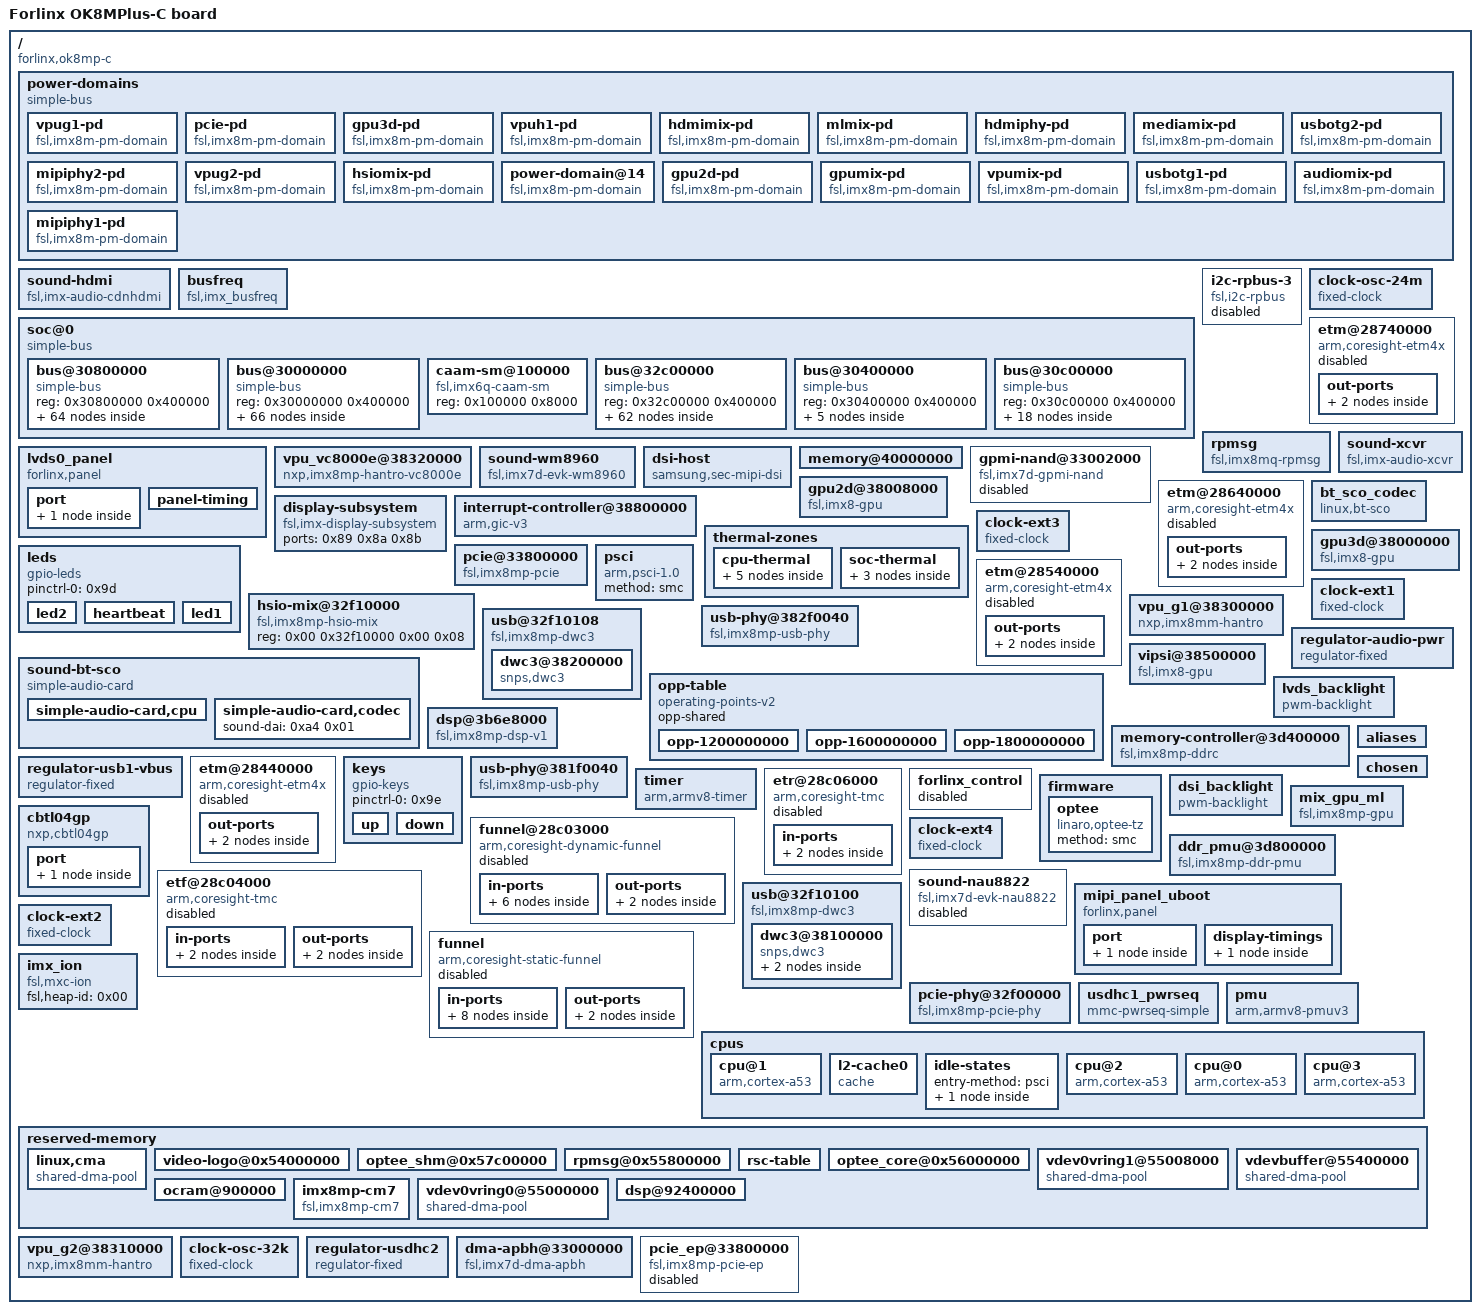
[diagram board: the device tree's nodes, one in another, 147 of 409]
/dts-v1/;

/ {
	#address-cells = <0x02>;
	model = "Forlinx OK8MPlus-C board";
	serial-number = "170e90004adaa6cb";
	#size-cells = <0x02>;
	interrupt-parent = <0x01>;
	compatible = "forlinx,ok8mp-c\0fsl,imx8mp-evk\0fsl,imx8mp";

	power-domains {
		compatible = "simple-bus";

		vpug1-pd {
			clocks = <0x03 0x106>;
			domain-name = "vpu_g1";
			#power-domain-cells = <0x00>;
			compatible = "fsl,imx8m-pm-domain";
			domain-index = <0x0a>;
			phandle = <0x83>;
			parent-domains = <0x0e>;
		};

		pcie-pd {
			domain-name = "pcie";
			#power-domain-cells = <0x00>;
			compatible = "fsl,imx8m-pm-domain";
			domain-index = <0x01>;
			phandle = <0x78>;
			parent-domains = <0x0c>;
		};

		gpu3d-pd {
			clocks = <0x03 0xf8 0x03 0x58>;
			domain-name = "gpu3d";
			#power-domain-cells = <0x00>;
			compatible = "fsl,imx8m-pm-domain";
			domain-index = <0x08>;
			phandle = <0x7d>;
			parent-domains = <0x0d>;
		};

		vpuh1-pd {
			clocks = <0x03 0x109>;
			domain-name = "vpu_h1";
			#power-domain-cells = <0x00>;
			compatible = "fsl,imx8m-pm-domain";
			domain-index = <0x0c>;
			phandle = <0x85>;
			parent-domains = <0x0e>;
		};

		hdmimix-pd {
			clocks = <0x03 0x116 0x03 0x63 0x03 0xa8>;
			domain-name = "hdmimix";
			#power-domain-cells = <0x00>;
			compatible = "fsl,imx8m-pm-domain";
			domain-index = <0x11>;
			phandle = <0x10>;
		};

		mlmix-pd {
			clocks = <0x03 0x69 0x03 0x6a 0x03 0x10b>;
			domain-name = "mlmix";
			#power-domain-cells = <0x00>;
			compatible = "fsl,imx8m-pm-domain";
			domain-index = <0x04>;
			phandle = <0x86>;
		};

		hdmiphy-pd {
			domain-name = "hdmi_phy";
			#power-domain-cells = <0x00>;
			compatible = "fsl,imx8m-pm-domain";
			domain-index = <0x12>;
			phandle = <0x6e>;
			parent-domains = <0x10>;
		};

		mediamix-pd {
			clocks = <0x03 0x10e 0x03 0x10d>;
			domain-name = "mediamix";
			#power-domain-cells = <0x00>;
			compatible = "fsl,imx8m-pm-domain";
			domain-index = <0x0d>;
			phandle = <0x0f>;
			rpm-always-on;
		};

		usbotg2-pd {
			domain-name = "usb_otg2";
			#power-domain-cells = <0x00>;
			compatible = "fsl,imx8m-pm-domain";
			domain-index = <0x03>;
			parent-domains = <0x0c>;
		};

		mipiphy2-pd {
			domain-name = "mipi_phy2";
			#power-domain-cells = <0x00>;
			compatible = "fsl,imx8m-pm-domain";
			domain-index = <0x10>;
			phandle = <0x75>;
			parent-domains = <0x0f>;
		};

		vpug2-pd {
			clocks = <0x03 0x10a>;
			domain-name = "vpu_g2";
			#power-domain-cells = <0x00>;
			compatible = "fsl,imx8m-pm-domain";
			domain-index = <0x0b>;
			phandle = <0x84>;
			parent-domains = <0x0e>;
		};

		hsiomix-pd {
			active-wakeup;
			domain-name = "hsiomix";
			#power-domain-cells = <0x00>;
			compatible = "fsl,imx8m-pm-domain";
			domain-index = <0x00>;
			phandle = <0x0c>;
			rpm-always-on;
		};

		power-domain@14 {
			clocks = <0x03 0x5c>;
			domain-name = "ispdwp";
			#power-domain-cells = <0x00>;
			compatible = "fsl,imx8m-pm-domain";
			domain-index = <0x0e>;
			phandle = <0x71>;
			parent-domains = <0x0f>;
		};

		gpu2d-pd {
			clocks = <0x03 0xf7>;
			domain-name = "gpu2d";
			#power-domain-cells = <0x00>;
			compatible = "fsl,imx8m-pm-domain";
			domain-index = <0x07>;
			phandle = <0x7e>;
			parent-domains = <0x0d>;
		};

		gpumix-pd {
			clocks = <0x03 0x107 0x03 0x66 0x03 0x65>;
			domain-name = "gpumix";
			#power-domain-cells = <0x00>;
			compatible = "fsl,imx8m-pm-domain";
			domain-index = <0x06>;
			phandle = <0x0d>;
		};

		vpumix-pd {
			clocks = <0x03 0x11a>;
			domain-name = "vpumix";
			#power-domain-cells = <0x00>;
			compatible = "fsl,imx8m-pm-domain";
			domain-index = <0x09>;
			phandle = <0x0e>;
		};

		usbotg1-pd {
			domain-name = "usb_otg1";
			#power-domain-cells = <0x00>;
			compatible = "fsl,imx8m-pm-domain";
			domain-index = <0x02>;
			parent-domains = <0x0c>;
		};

		audiomix-pd {
			clocks = <0x03 0x11c 0x03 0x5a>;
			domain-name = "audiomix";
			#power-domain-cells = <0x00>;
			compatible = "fsl,imx8m-pm-domain";
			domain-index = <0x05>;
			phandle = <0x56>;
		};

		mipiphy1-pd {
			domain-name = "mipi_phy1";
			#power-domain-cells = <0x00>;
			compatible = "fsl,imx8m-pm-domain";
			domain-index = <0x0f>;
			phandle = <0x5a>;
			parent-domains = <0x0f>;
			rpm-always-on;
		};
	};

	sound-hdmi {
		constraint-rate = <0xac44 0x15888 0x2b110 0x7d00 0xbb80 0x17700 0x2ee00>;
		model = "audio-hdmi";
		hdmi-out;
		compatible = "fsl,imx-audio-cdnhdmi";
		status = "okay";
		audio-cpu = <0xa5>;
	};

	busfreq {
		clock-names = "dram_pll\0dram_alt_src\0dram_apb_src\0dram_apb_pre_div\0dram_core\0dram_alt_root\0sys_pll1_40m\0sys_pll1_100m\0sys_pll2_333m\0noc_div\0ahb_div\0main_axi_src\0osc_24m\0sys_pll1_800m\0dram_pll_div";
		clocks = <0x03 0x29 0x03 0x70 0x03 0x71 0x03 0x71 0x03 0x11e 0x03 0x11d 0x03 0x30 0x03 0x32 0x03 0x3f 0x03 0x67 0x03 0x6b 0x03 0x5d 0x03 0x02 0x03 0x38 0x03 0x15>;
		compatible = "fsl,imx_busfreq";
	};

	soc@0 {
		#address-cells = <0x01>;
		#size-cells = <0x01>;
		compatible = "simple-bus";
		ranges = <0x00 0x00 0x00 0x3e000000>;

		bus@30800000 {
			#address-cells = <0x01>;
			#size-cells = <0x01>;
			compatible = "simple-bus";
			ranges;
			reg = <0x30800000 0x400000>;

			spi@30820000 {
				#address-cells = <0x01>;
				clock-names = "ipg\0per";
				assigned-clocks = <0x03 0x95>;
				assigned-clock-parents = <0x03 0x38>;
				assigned-clock-rates = <0x4c4b400>;
				interrupts = <0x00 0x1f 0x04>;
				clocks = <0x03 0xbd 0x03 0xbd>;
				#size-cells = <0x00>;
				dma-names = "rx\0tx";
				compatible = "fsl,imx8mp-ecspi\0fsl,imx6ul-ecspi";
				status = "disabled";
				reg = <0x30820000 0x10000>;
				dmas = <0x22 0x00 0x07 0x01 0x22 0x01 0x07 0x02>;
			};

			ethernet@30bf0000 {
				pinctrl-names = "default";
				phy-mode = "rgmii-id";
				intf_mode = <0x29 0x04>;
				nvmem-cells = <0x52>;
				pinctrl-0 = <0x53>;
				clock-names = "stmmaceth\0pclk\0ptp_ref\0tx";
				assigned-clocks = <0x03 0x5e 0x03 0x82 0x03 0x81>;
				assigned-clock-parents = <0x03 0x36 0x03 0x3a 0x03 0x3b>;
				local-mac-address = [26 6d dd 76 00 fb];
				assigned-clock-rates = <0x00 0x5f5e100 0x7735940>;
				interrupts = <0x00 0x86 0x04 0x00 0x87 0x04>;
				clocks = <0x03 0xed 0x03 0xe1 0x03 0x82 0x03 0x81>;
				nvmem_macaddr_swap;
				reset-gpio = <0x25 0x05 0x01>;
				compatible = "nxp,imx8mp-dwmac-eqos\0snps,dwmac-5.10a";
				status = "okay";
				interrupt-names = "eth_wake_irq\0macirq";
				nvmem-cell-names = "mac-address";
				reg = <0x30bf0000 0x10000>;
				phy-handle = <0x54>;

				mdio {
					#address-cells = <0x01>;
					#size-cells = <0x00>;
					compatible = "snps,dwmac-mdio";

					ethernet-phy@1 {
						at803x,vddio-1p8v;
						at803x,hibernate-disable;
						compatible = "ethernet-phy-ieee802.3-c22";
						eee-broken-1000t;
						reg = <0x01>;
						phandle = <0x54>;
					};
				};
			};

			i2c@30a50000 {
				pinctrl-names = "default";
				#address-cells = <0x01>;
				pinctrl-0 = <0x3e>;
				interrupts = <0x00 0x26 0x04>;
				clocks = <0x03 0xd0>;
				#size-cells = <0x00>;
				clock-frequency = <0x186a0>;
				compatible = "fsl,imx8mp-i2c\0fsl,imx21-i2c";
				status = "okay";
				reg = <0x30a50000 0x10000>;

				ft5316@38 {
					pinctrl-names = "default";
					pinctrl-0 = <0x3f>;
					interrupts = <0x0c 0x02>;
					interrupt-parent = <0x2e>;
					touchscreen-size-x = <0x400>;
					compatible = "edt,edt-ft5306";
					reg = <0x38>;
					touchscreen-size-y = <0x258>;
				};
			};

			serial@30a60000 {
				clock-names = "ipg\0per";
				interrupts = <0x00 0x1d 0x04>;
				clocks = <0x03 0xfe 0x03 0xfe>;
				dma-names = "rx\0tx";
				compatible = "fsl,imx8mp-uart\0fsl,imx6q-uart";
				status = "disabled";
				reg = <0x30a60000 0x10000>;
				dmas = <0x22 0x1c 0x04 0x00 0x22 0x1d 0x04 0x00>;
			};

			mmc@30b40000 {
				fsl,tuning-start-tap = <0x14>;
				pinctrl-names = "default\0state_100mhz\0state_200mhz";
				pinctrl-2 = <0x43 0x41>;
				pinctrl-0 = <0x40 0x41>;
				clock-names = "ipg\0ahb\0per";
				assigned-clocks = <0x03 0x88>;
				bus-width = <0x04>;
				non-removable;
				assigned-clock-rates = <0x17d78400>;
				interrupts = <0x00 0x16 0x04>;
				clocks = <0x03 0x00 0x03 0x5f 0x03 0x101>;
				keep-power-in-suspend;
				pm-ignore-notify;
				compatible = "fsl,imx8mm-usdhc\0fsl,imx7d-usdhc";
				pinctrl-1 = <0x42 0x41>;
				status = "okay";
				fsl,tuning-step = <0x02>;
				mmc-pwrseq = <0x44>;
				reg = <0x30b40000 0x10000>;
			};

			i2c@30ad0000 {
				#address-cells = <0x01>;
				interrupts = <0x00 0x4c 0x04>;
				clocks = <0x03 0xe7>;
				#size-cells = <0x00>;
				compatible = "fsl,imx8mp-i2c\0fsl,imx21-i2c";
				status = "disabled";
				reg = <0x30ad0000 0x10000>;
			};

			can@308d0000 {
				fsl,clk-source = <0x00>;
				pinctrl-names = "default";
				fsl,stop-mode = <0x29 0x10 0x05 0x10 0x15>;
				pinctrl-0 = <0x2b>;
				clock-names = "ipg\0per";
				assigned-clocks = <0x03 0x75>;
				assigned-clock-parents = <0x03 0x30>;
				assigned-clock-rates = <0x2625a00>;
				interrupts = <0x00 0x90 0x04>;
				clocks = <0x03 0x6e 0x03 0xea>;
				compatible = "fsl,imx8mp-flexcan\0fsl,imx6q-flexcan";
				status = "okay";
				reg = <0x308d0000 0x10000>;
			};

			spi@30830000 {
				pinctrl-names = "default";
				#address-cells = <0x01>;
				pinctrl-0 = <0x23 0x24>;
				clock-names = "ipg\0per";
				assigned-clocks = <0x03 0x96>;
				assigned-clock-parents = <0x03 0x38>;
				assigned-clock-rates = <0x4c4b400>;
				interrupts = <0x00 0x20 0x04>;
				clocks = <0x03 0xbe 0x03 0xbe>;
				#size-cells = <0x00>;
				dma-names = "rx\0tx";
				compatible = "fsl,imx8mp-ecspi\0fsl,imx6ul-ecspi";
				status = "okay";
				reg = <0x30830000 0x10000>;
				dmas = <0x22 0x02 0x07 0x01 0x22 0x03 0x07 0x02>;
				fsl,spi-num-chipselects = <0x01>;
				cs-gpios = <0x25 0x0d 0x01>;

				spi@0 {
					spi-max-frequency = <0x7a120>;
					compatible = "rohm,dh2228fv";
					reg = <0x00>;
				};
			};

			i2c@30a20000 {
				pinctrl-names = "default";
				#address-cells = <0x01>;
				pinctrl-0 = <0x2c>;
				interrupts = <0x00 0x23 0x04>;
				clocks = <0x03 0xcd>;
				#size-cells = <0x00>;
				clock-frequency = <0x186a0>;
				compatible = "fsl,imx8mp-i2c\0fsl,imx21-i2c";
				status = "okay";
				reg = <0x30a20000 0x10000>;

				pca9450@25 {
					gpio_intr = <0x2e 0x03 0x01>;
					pinctrl-0 = <0x2d>;
					compatible = "nxp,pca9450";
					reg = <0x25>;

					regulators {
						pca9450,pmic-buck2-dvs-voltage = <0xe7ef0 0xcf850>;
						#address-cells = <0x01>;
						pca9450,pmic-buck2-uses-i2c-dvs;
						#size-cells = <0x00>;

						regulator@1 {
							regulator-max-microvolt = <0x2160ec>;
							regulator-boot-on;
							regulator-always-on;
							regulator-min-microvolt = <0x927c0>;
							regulator-ramp-delay = <0xc35>;
							reg = <0x01>;
							phandle = <0x07>;
							regulator-compatible = "buck2";
						};

						regulator@8 {
							regulator-max-microvolt = <0x325aa0>;
							regulator-boot-on;
							regulator-always-on;
							regulator-min-microvolt = <0xc3500>;
							reg = <0x08>;
							regulator-compatible = "ldo3";
						};

						regulator@6 {
							regulator-max-microvolt = <0x325aa0>;
							regulator-boot-on;
							regulator-always-on;
							regulator-min-microvolt = <0x186a00>;
							reg = <0x06>;
							regulator-compatible = "ldo1";
						};

						regulator@4 {
							regulator-max-microvolt = <0x33e140>;
							regulator-boot-on;
							regulator-always-on;
							regulator-min-microvolt = <0x927c0>;
							reg = <0x04>;
							regulator-compatible = "buck5";
						};

						regulator@0 {
							regulator-max-microvolt = <0x2160ec>;
							regulator-boot-on;
							regulator-always-on;
							regulator-min-microvolt = <0x927c0>;
							regulator-ramp-delay = <0xc35>;
							reg = <0x00>;
							regulator-compatible = "buck1";
						};

						regulator@9 {
							regulator-max-microvolt = <0x325aa0>;
							regulator-boot-on;
							regulator-always-on;
							regulator-min-microvolt = <0xc3500>;
							reg = <0x09>;
							regulator-compatible = "ldo4";
						};

						regulator@7 {
							regulator-max-microvolt = <0x118c30>;
							regulator-boot-on;
							regulator-always-on;
							regulator-min-microvolt = <0xc3500>;
							reg = <0x07>;
							regulator-compatible = "ldo2";
						};

						regulator@5 {
							regulator-max-microvolt = <0x33e140>;
							regulator-boot-on;
							regulator-always-on;
							regulator-min-microvolt = <0x927c0>;
							reg = <0x05>;
							regulator-compatible = "buck6";
						};

						regulator@3 {
							regulator-max-microvolt = <0x33e140>;
							regulator-boot-on;
							regulator-always-on;
							regulator-min-microvolt = <0x927c0>;
							reg = <0x03>;
							regulator-compatible = "buck4";
						};

						regulator@10 {
							regulator-max-microvolt = <0x325aa0>;
							regulator-min-microvolt = <0x1b7740>;
							reg = <0x0a>;
							regulator-compatible = "ldo5";
						};
					};
				};
			};

			crypto@30900000 {
				#address-cells = <0x01>;
				clock-names = "aclk\0ipg";
				interrupts = <0x00 0x5b 0x04>;
				clocks = <0x03 0x6b 0x03 0x6e>;
				#size-cells = <0x01>;
				compatible = "fsl,sec-v4.0";
				ranges = <0x00 0x30900000 0x40000>;
				reg = <0x30900000 0x40000>;

				jr@2000 {
					interrupts = <0x00 0x6a 0x04>;
					compatible = "fsl,sec-v4.0-job-ring";
					reg = <0x2000 0x1000>;
				};

				jr@1000 {
					interrupts = <0x00 0x69 0x04>;
					compatible = "fsl,sec-v4.0-job-ring";
					reg = <0x1000 0x1000>;
				};

				jr@3000 {
					interrupts = <0x00 0x72 0x04>;
					compatible = "fsl,sec-v4.0-job-ring";
					status = "disabled";
					reg = <0x3000 0x1000>;
				};
			};

			mu@30aa0000 {
				clock-names = "mu";
				interrupts = <0x00 0x58 0x04>;
				clocks = <0x03 0xd5>;
				#mbox-cells = <0x02>;
				compatible = "fsl,imx8mp-mu\0fsl,imx6sx-mu";
				reg = <0x30aa0000 0x10000>;
				phandle = <0x08>;
			};

			spi@30bb0000 {
				pinctrl-names = "default";
				#address-cells = <0x01>;
				pinctrl-0 = <0x4e>;
				clock-names = "fspi\0fspi_en";
				reg-names = "fspi_base\0fspi_mmap";
				assigned-clocks = <0x03 0x87>;
				assigned-clock-rates = <0x4c4b400>;
				interrupts = <0x00 0x6b 0x04>;
				clocks = <0x03 0xe2 0x03 0xe2>;
				#size-cells = <0x00>;
				compatible = "nxp,imx8mm-fspi";
				status = "okay";
				reg = <0x30bb0000 0x10000 0x8000000 0x10000000>;

				mt25qu256aba@0 {
					#address-cells = <0x01>;
					spi-tx-bus-width = <0x04>;
					#size-cells = <0x01>;
					spi-max-frequency = <0x2faf080>;
					spi-rx-bus-width = <0x04>;
					compatible = "jedec,spi-nor";
					reg = <0x00>;
				};
			};

			serial@30880000 {
				pinctrl-names = "default";
				fsl,uart-has-rtscts;
				pinctrl-0 = <0x27>;
				clock-names = "ipg\0per";
				assigned-clocks = <0x03 0x90>;
				assigned-clock-parents = <0x03 0x31>;
				interrupts = <0x00 0x1c 0x04>;
				clocks = <0x03 0xfd 0x03 0xfd>;
				dma-names = "rx\0tx";
				compatible = "fsl,imx8mp-uart\0fsl,imx6q-uart";
				status = "okay";
				reg = <0x30880000 0x10000>;
				dmas = <0x22 0x1a 0x04 0x00 0x22 0x1b 0x04 0x00>;
			};

			dma-controller@30bd0000 {
				clock-names = "ipg\0ahb";
				interrupts = <0x00 0x02 0x04>;
				clocks = <0x03 0xec 0x03 0x6b>;
				fsl,sdma-ram-script-name = "imx/sdma/sdma-imx7d.bin";
				compatible = "fsl,imx8mq-sdma\0fsl,imx7d-sdma";
				reg = <0x30bd0000 0x10000>;
				phandle = <0x22>;
				#dma-cells = <0x03>;
			};

			mmc@30b50000 {
				fsl,tuning-start-tap = <0x14>;
				pinctrl-names = "default\0state_100mhz\0state_200mhz";
				pinctrl-2 = <0x48 0x46>;
				pinctrl-0 = <0x45 0x46>;
				clock-names = "ipg\0ahb\0per";
				assigned-clocks = <0x03 0x89>;
				bus-width = <0x04>;
				assigned-clock-rates = <0x17d78400>;
				interrupts = <0x00 0x17 0x04>;
				clocks = <0x03 0x00 0x03 0x5f 0x03 0x102>;
				vmmc-supply = <0x4a>;
				compatible = "fsl,imx8mm-usdhc\0fsl,imx7d-usdhc";
				pinctrl-1 = <0x47 0x46>;
				status = "okay";
				fsl,tuning-step = <0x02>;
				reg = <0x30b50000 0x10000>;
				cd-gpios = <0x49 0x0c 0x01>;
			};

			i2c@30ae0000 {
				#address-cells = <0x01>;
				interrupts = <0x00 0x4d 0x04>;
				clocks = <0x03 0xe8>;
				#size-cells = <0x00>;
				compatible = "fsl,imx8mp-i2c\0fsl,imx21-i2c";
				status = "disabled";
				reg = <0x30ae0000 0x10000>;
			};

			spi@30840000 {
				#address-cells = <0x01>;
				clock-names = "ipg\0per";
				assigned-clocks = <0x03 0xb3>;
				assigned-clock-parents = <0x03 0x38>;
				assigned-clock-rates = <0x4c4b400>;
				interrupts = <0x00 0x21 0x04>;
				clocks = <0x03 0xbf 0x03 0xbf>;
				#size-cells = <0x00>;
				dma-names = "rx\0tx";
				compatible = "fsl,imx8mp-ecspi\0fsl,imx6ul-ecspi";
				status = "disabled";
				reg = <0x30840000 0x10000>;
				dmas = <0x22 0x04 0x07 0x01 0x22 0x05 0x07 0x02>;
			};

			i2c@30a30000 {
				pinctrl-names = "default";
				#address-cells = <0x01>;
				pinctrl-0 = <0x2f>;
				interrupts = <0x00 0x24 0x04>;
				clocks = <0x03 0xce>;
				#size-cells = <0x00>;
				clock-frequency = <0x186a0>;
				compatible = "fsl,imx8mp-i2c\0fsl,imx21-i2c";
				status = "okay";
				reg = <0x30a30000 0x10000>;

				basler_camera_vvcam@36 {
					csi_id = <0x00>;
					compatible = "basler,basler-camera-vvcam\0basler-camera-vvcam";
					status = "okay";
					reg = <0x36>;

					port {

						endpoint {
							data-lanes = <0x01 0x02 0x03 0x04>;
							clock-lanes = <0x00>;
							remote-endpoint = <0x34>;
							phandle = <0x73>;
							link-frequencies = <0x00 0xec82e00>;
						};
					};
				};

				ov5645_mipi@3c {
					pinctrl-names = "default";
					pinctrl-0 = <0x30 0x31>;
					mipi_csi;
					clock-names = "xclk";
					assigned-clocks = <0x03 0xa5>;
					assigned-clock-parents = <0x03 0x02>;
					assigned-clock-rates = <0x16e3600>;
					clocks = <0x03 0xa5>;
					mclk_source = <0x00>;
					mclk = <0x16e3600>;
					clock-frequency = <0x16e3600>;
					csi_id = <0x01>;
					reset-gpios = <0x32 0x13 0x01>;
					compatible = "ovti,ov5645";
					status = "okay";
					enable-gpios = <0x32 0x14 0x00>;
					reg = <0x3c>;

					port {

						endpoint {
							data-lanes = <0x01 0x02>;
							clock-lanes = <0x00>;
							remote-endpoint = <0x33>;
							phandle = <0x76>;
							link-frequencies = <0x00 0x1406f400>;
						};
					};
				};
			};

			serial@30890000 {
				pinctrl-names = "default";
				pinctrl-0 = <0x28>;
				clock-names = "ipg\0per";
				interrupts = <0x00 0x1b 0x04>;
				clocks = <0x03 0xfc 0x03 0xfc>;
				compatible = "fsl,imx8mp-uart\0fsl,imx6q-uart";
				status = "okay";
				reg = <0x30890000 0x10000>;
			};

			mmc@30b60000 {
				fsl,tuning-start-tap = <0x14>;
				pinctrl-names = "default\0state_100mhz\0state_200mhz";
				pinctrl-2 = <0x4d>;
				pinctrl-0 = <0x4b>;
				clock-names = "ipg\0ahb\0per";
				assigned-clocks = <0x03 0xa9>;
				bus-width = <0x08>;
				non-removable;
				assigned-clock-rates = <0x17d78400>;
				interrupts = <0x00 0x18 0x04>;
				clocks = <0x03 0x00 0x03 0x5f 0x03 0x115>;
				compatible = "fsl,imx8mm-usdhc\0fsl,imx7d-usdhc";
				pinctrl-1 = <0x4c>;
				status = "okay";
				fsl,tuning-step = <0x02>;
				reg = <0x30b60000 0x10000>;
			};

			ethernet@30be0000 {
				pinctrl-names = "default";
				phy-mode = "rgmii-id";
				fsl,num-rx-queues = <0x03>;
				nvmem-cells = <0x4f>;
				pinctrl-0 = <0x50>;
				fsl,wakeup_irq = <0x02>;
				clock-names = "ipg\0ahb\0ptp\0enet_clk_ref\0enet_out";
				assigned-clocks = <0x03 0x5e 0x03 0x84 0x03 0x83 0x03 0x84>;
				assigned-clock-parents = <0x03 0x36 0x03 0x3a 0x03 0x3b>;
				fsl,num-tx-queues = <0x03>;
				local-mac-address = [26 6d dd 76 00 fa];
				assigned-clock-rates = <0x00 0x00 0x7735940 0x5f5e100>;
				interrupts = <0x00 0x76 0x04 0x00 0x77 0x04 0x00 0x78 0x04>;
				clocks = <0x03 0xc0 0x03 0xf2 0x03 0x84 0x03 0x83 0x03 0x85>;
				stop-mode = <0x29 0x10 0x03>;
				nvmem_macaddr_swap;
				reset-gpio = <0x25 0x04 0x01>;
				compatible = "fsl,imx8mm-fec\0fsl,imx8mq-fec\0fsl,imx6sx-fec";
				status = "okay";
				nvmem-cell-names = "mac-address";
				fsl,magic-packet;
				reg = <0x30be0000 0x10000>;
				phy-handle = <0x51>;

				mdio {
					#address-cells = <0x01>;
					#size-cells = <0x00>;

					ethernet-phy@1 {
						at803x,vddio-1p8v;
						compatible = "ethernet-phy-ieee802.3-c22";
						eee-broken-1000t;
						reg = <0x01>;
						phandle = <0x51>;
					};
				};
			};

			i2c@30a40000 {
				pinctrl-names = "default";
				#address-cells = <0x01>;
				pinctrl-0 = <0x35>;
				interrupts = <0x00 0x25 0x04>;
				clocks = <0x03 0xcf>;
				#size-cells = <0x00>;
				clock-frequency = <0x186a0>;
				compatible = "fsl,imx8mp-i2c\0fsl,imx21-i2c";
				status = "okay";
				reg = <0x30a40000 0x10000>;

				nau8822@1a {
					SPKVDD1-supply = <0x3c>;
					clock-names = "mclk";
					clocks = <0x3b 0x09>;
					compatible = "nuvoton,nau8822";
					wlf,shared-lrclk;
					status = "disabled";
					reg = <0x1a>;
					phandle = <0xa9>;
				};

				touchscreen@14 {
					pinctrl-names = "default";
					pinctrl-0 = <0x3d>;
					irq-gpios = <0x2e 0x00 0x00>;
					interrupts = <0x00 0x02>;
					interrupt-parent = <0x2e>;
					touchscreen-size-x = <0x500>;
					reset-gpios = <0x2e 0x0a 0x00>;
					compatible = "goodix,gt928";
					reg = <0x14>;
					touchscreen-swapped-x-y;
					edge-failling-trigger;
					touchscreen-size-y = <0x320>;
				};

				rx8010@32 {
					compatible = "epson,rx8010";
					status = "okay";
					reg = <0x32>;
				};

				wm8960@1a {
					SPKVDD1-supply = <0x3c>;
					clock-names = "mclk";
					clocks = <0x3b 0x09>;
					compatible = "wlf,wm8960";
					wlf,shared-lrclk;
					status = "okay";
					reg = <0x1a>;
					phandle = <0xa7>;
				};

				pcf8563@51 {
					clock-output-names = "pcf8563-clkout";
					#clock-cells = <0x00>;
					compatible = "nxp,pcf8563";
					reg = <0x51>;
				};

				typec-portc@22 {
					pinctrl-names = "default";
					pinctrl-0 = <0x36>;
					interrupts = <0x13 0x08>;
					vbus-supply = <0x37>;
					interrupt-parent = <0x38>;
					compatible = "fcs,fusb302";
					status = "okay";
					reg = <0x22>;
					phandle = <0x7f>;

					connector {
						sink-pdos = <0x4019096>;
						power-role = "dual";
						source-pdos = <0x4019096>;
						data-role = "dual";
						label = "USB-C";
						try-power-role = "sink";
						compatible = "usb-c-connector";
						op-sink-microwatt = <0x7270e0>;

						ports {
							#address-cells = <0x01>;
							#size-cells = <0x00>;

							port@1 {
								reg = <0x01>;

								endpoint {
									remote-endpoint = <0x3a>;
									phandle = <0xa1>;
								};
							};
						};
					};

					port {

						endpoint {
							remote-endpoint = <0x39>;
							phandle = <0x81>;
						};
					};
				};
			};

			serial@30860000 {
				pinctrl-names = "default";
				fsl,uart-has-rtscts;
				pinctrl-0 = <0x26>;
				clock-names = "ipg\0per";
				assigned-clocks = <0x03 0x8e>;
				assigned-clock-parents = <0x03 0x31>;
				interrupts = <0x00 0x1a 0x04>;
				clocks = <0x03 0xfb 0x03 0xfb>;
				dma-names = "rx\0tx";
				compatible = "fsl,imx8mp-uart\0fsl,imx6q-uart";
				status = "okay";
				reg = <0x30860000 0x10000>;
				dmas = <0x22 0x16 0x04 0x00 0x22 0x17 0x04 0x00>;
			};

			can@308c0000 {
				fsl,clk-source = <0x00>;
				pinctrl-names = "default";
				fsl,stop-mode = <0x29 0x10 0x04 0x10 0x14>;
				pinctrl-0 = <0x2a>;
				clock-names = "ipg\0per";
				assigned-clocks = <0x03 0x74>;
				assigned-clock-parents = <0x03 0x30>;
				assigned-clock-rates = <0x2625a00>;
				interrupts = <0x00 0x8e 0x04>;
				clocks = <0x03 0x6e 0x03 0xe9>;
				compatible = "fsl,imx8mp-flexcan\0fsl,imx6q-flexcan";
				status = "okay";
				reg = <0x308c0000 0x10000>;
			};
		};

		bus@30000000 {
			#address-cells = <0x01>;
			#size-cells = <0x01>;
			compatible = "simple-bus";
			ranges;
			reg = <0x30000000 0x400000>;

			snvs@30370000 {
				compatible = "fsl,sec-v4.0-mon\0syscon\0simple-mfd";
				reg = <0x30370000 0x10000>;
				phandle = <0x19>;

				snvs-powerkey {
					clock-names = "snvs";
					wakeup-source;
					interrupts = <0x00 0x04 0x04>;
					clocks = <0x03 0xf9>;
					compatible = "fsl,sec-v4.0-pwrkey";
					linux,keycode = <0x74>;
					regmap = <0x19>;
				};

				snvs-rtc-lp {
					clock-names = "snvs-rtc";
					interrupts = <0x00 0x13 0x04 0x00 0x14 0x04>;
					clocks = <0x03 0xf9>;
					offset = <0x34>;
					compatible = "fsl,sec-v4.0-mon-rtc-lp";
					regmap = <0x19>;
				};
			};

			ocotp-ctrl@30350000 {
				#address-cells = <0x01>;
				clocks = <0x03 0xd6>;
				#size-cells = <0x01>;
				compatible = "fsl,imx8mp-ocotp\0fsl,imx8mm-ocotp\0syscon";
				reg = <0x30350000 0x10000>;

				mac-address@650 {
					reg = <0x96 0x06>;
					phandle = <0x52>;
				};

				mac-address@640 {
					reg = <0x90 0x06>;
					phandle = <0x4f>;
				};

				speed-grade@10 {
					reg = <0x10 0x04>;
					phandle = <0x05>;
				};
			};

			clock-controller@30380000 {
				clock-names = "osc_32k\0osc_24m\0clk_ext1\0clk_ext2\0clk_ext3\0clk_ext4";
				assigned-clocks = <0x03 0x67 0x03 0x68 0x03 0x94 0x03 0x6c 0x03 0x48 0x03 0x6f 0x03 0x12 0x03 0x13 0x03 0x14>;
				assigned-clock-parents = <0x03 0x41 0x03 0x38 0x03 0x40 0x03 0x38 0x03 0x38>;
				init-on-array = <0x10c>;
				assigned-clock-rates = <0x3b9aca00 0x2faf0800 0x1dcd6500 0x17d78400 0x2faf0800 0x17d78400 0x17700000 0x15888000 0x3df582e0>;
				clocks = <0x1a 0x1b 0x1c 0x1d 0x1e 0x1f>;
				#clock-cells = <0x01>;
				compatible = "fsl,imx8mp-ccm";
				reg = <0x30380000 0x10000>;
				phandle = <0x03>;
			};

			src@30390000 {
				#reset-cells = <0x01>;
				interrupts = <0x00 0x59 0x04>;
				compatible = "fsl,imx8mp-src\0fsl,imx8mq-src\0syscon";
				reg = <0x30390000 0x10000>;
				phandle = <0x79>;
			};

			gpio@30230000 {
				gpio-controller;
				interrupts = <0x00 0x46 0x04 0x00 0x47 0x04>;
				clocks = <0x03 0xc4>;
				compatible = "fsl,imx8mp-gpio\0fsl,imx35-gpio";
				#interrupt-cells = <0x02>;
				reg = <0x30230000 0x10000>;
				phandle = <0x38>;
				#gpio-cells = <0x02>;
				interrupt-controller;
			};

			watchdog@30280000 {
				pinctrl-names = "default";
				pinctrl-0 = <0x17>;
				interrupts = <0x00 0x4e 0x04>;
				clocks = <0x03 0x103>;
				fsl,ext-reset-output;
				compatible = "fsl,imx8mp-wdt\0fsl,imx21-wdt";
				status = "okay";
				reg = <0x30280000 0x10000>;
			};

			gpio@30200000 {
				gpio-controller;
				interrupts = <0x00 0x40 0x04 0x00 0x41 0x04>;
				clocks = <0x03 0xc1>;
				compatible = "fsl,imx8mp-gpio\0fsl,imx35-gpio";
				#interrupt-cells = <0x02>;
				reg = <0x30200000 0x10000>;
				phandle = <0x2e>;
				#gpio-cells = <0x02>;
				interrupt-controller;
			};

			gpio@30240000 {
				gpio-controller;
				interrupts = <0x00 0x48 0x04 0x00 0x49 0x04>;
				clocks = <0x03 0xc5>;
				compatible = "fsl,imx8mp-gpio\0fsl,imx35-gpio";
				#interrupt-cells = <0x02>;
				reg = <0x30240000 0x10000>;
				phandle = <0x25>;
				#gpio-cells = <0x02>;
				interrupt-controller;
			};

			caam-snvs@30370000 {
				clock-names = "ipg";
				clocks = <0x03 0xf9>;
				compatible = "fsl,imx6q-caam-snvs";
				reg = <0x30370000 0x10000>;
			};

			gpio@30210000 {
				gpio-controller;
				interrupts = <0x00 0x42 0x04 0x00 0x43 0x04>;
				clocks = <0x03 0xc2>;
				compatible = "fsl,imx8mp-gpio\0fsl,imx35-gpio";
				#interrupt-cells = <0x02>;
				reg = <0x30210000 0x10000>;
				phandle = <0x49>;
				#gpio-cells = <0x02>;
				interrupt-controller;
			};

			anatop@30360000 {
				compatible = "fsl,imx8mp-anatop\0fsl,imx8mm-anatop\0syscon";
				reg = <0x30360000 0x10000>;
			};

			iomuxc-gpr@30340000 {
				compatible = "fsl,imx8mp-iomuxc-gpr\0fsl,imx7d-iomuxc-gpr\0fsl,imx6q-iomuxc-gpr\0syscon";
				reg = <0x30340000 0x10000>;
				phandle = <0x29>;
			};

			pinctrl@30330000 {
				pinctrl-names = "default";
				pinctrl-0 = <0x18>;
				compatible = "fsl,imx8mp-iomuxc";
				reg = <0x30330000 0x10000>;

				uart1grp {
					fsl,pins = <0x220 0x480 0x5e8 0x00 0x04 0x140 0x224 0x484 0x00 0x00 0x00 0x140 0x230 0x490 0x00 0x01 0x00 0x140 0x234 0x494 0x5e4 0x01 0x05 0x140>;
					phandle = <0x26>;
				};

				usdhc2grp-100mhz {
					fsl,pins = <0xc0 0x320 0x00 0x00 0x00 0x194 0xc4 0x324 0x00 0x00 0x00 0x1d4 0xc8 0x328 0x00 0x00 0x00 0x1d4 0xcc 0x32c 0x00 0x00 0x00 0x1d4 0xd0 0x330 0x00 0x00 0x00 0x1d4 0xd4 0x334 0x00 0x00 0x00 0x1d4 0x24 0x284 0x00 0x01 0x00 0xc1>;
					phandle = <0x47>;
				};

				flexcan2grp {
					fsl,pins = <0x1b4 0x414 0x550 0x03 0x01 0x154 0x1b0 0x410 0x00 0x03 0x00 0x154>;
					phandle = <0x2b>;
				};

				wdoggrp {
					fsl,pins = <0x1c 0x27c 0x00 0x01 0x00 0xc6>;
					phandle = <0x17>;
				};

				gpiokeygrp {
					fsl,pins = <0x1a8 0x408 0x00 0x05 0x00 0x159 0x190 0x3f0 0x00 0x05 0x00 0x159>;
					phandle = <0x9e>;
				};

				typec1grp {
					fsl,pins = <0x194 0x3f4 0x00 0x05 0x00 0x1c4>;
					phandle = <0x36>;
				};

				usb1grp {
					fsl,pins = <0x4c 0x2ac 0x00 0x00 0x00 0x19>;
					phandle = <0x9f>;
				};

				mipi_dsi_en {
					fsl,pins = <0x30 0x290 0x00 0x00 0x00 0x16>;
					phandle = <0x5d>;
				};

				csi0_rst_grp {
					fsl,pins = <0x12c 0x38c 0x00 0x05 0x00 0x19>;
					phandle = <0x31>;
				};

				ecspi2cs {
					fsl,pins = <0x1fc 0x45c 0x00 0x05 0x00 0x40000>;
					phandle = <0x24>;
				};

				i2c2grp {
					fsl,pins = <0x208 0x468 0x5ac 0x00 0x02 0x400001c3 0x20c 0x46c 0x5b0 0x00 0x02 0x400001c3>;
					phandle = <0x2f>;
				};

				usdhc3grp-200mhz {
					fsl,pins = <0x124 0x384 0x604 0x02 0x01 0x196 0x128 0x388 0x60c 0x02 0x01 0x1d6 0x108 0x368 0x610 0x02 0x01 0x1d6 0x10c 0x36c 0x614 0x02 0x01 0x1d6 0x110 0x370 0x618 0x02 0x01 0x1d6 0x114 0x374 0x61c 0x02 0x01 0x1d6 0x11c 0x37c 0x620 0x02 0x01 0x1d6 0xec 0x34c 0x624 0x02 0x01 0x1d6 0xf0 0x350 0x628 0x02 0x01 0x1d6 0xf4 0x354 0x62c 0x02 0x01 0x1d6 0xe8 0x348 0x630 0x02 0x01 0x196>;
					phandle = <0x4d>;
				};

				usdhc2grp {
					fsl,pins = <0xc0 0x320 0x00 0x00 0x00 0x190 0xc4 0x324 0x00 0x00 0x00 0x1d0 0xc8 0x328 0x00 0x00 0x00 0x1d0 0xcc 0x32c 0x00 0x00 0x00 0x1d0 0xd0 0x330 0x00 0x00 0x00 0x1d0 0xd4 0x334 0x00 0x00 0x00 0x1d0 0x24 0x284 0x00 0x01 0x00 0xc1>;
					phandle = <0x45>;
				};

				usdhc1grp-gpio {
					fsl,pins = <0xac 0x30c 0x00 0x05 0x00 0x41>;
					phandle = <0x41>;
				};

				gt928_int_iogrp {
					fsl,pins = <0x14 0x274 0x00 0x00 0x00 0x16 0x3c 0x29c 0x00 0x00 0x00 0x16>;
					phandle = <0x3d>;
				};

				uart3grp {
					fsl,pins = <0x1e0 0x440 0x5f8 0x01 0x04 0x140 0x1e4 0x444 0x00 0x01 0x00 0x140>;
					phandle = <0x27>;
				};

				gpioledgrp {
					fsl,pins = <0x1e8 0x448 0x00 0x05 0x00 0x19 0x1ec 0x44c 0x00 0x05 0x00 0x19>;
					phandle = <0x9d>;
				};

				pmicirq {
					fsl,pins = <0x20 0x280 0x00 0x00 0x00 0x41>;
					phandle = <0x2d>;
				};

				flexcan1grp {
					fsl,pins = <0x1ac 0x40c 0x54c 0x03 0x01 0x154 0x1a0 0x400 0x00 0x03 0x00 0x154>;
					phandle = <0x2a>;
				};

				sai3grp {
					fsl,pins = <0x1c4 0x424 0x4ec 0x00 0x01 0xd6 0x1c8 0x428 0x4e8 0x00 0x01 0xd6 0x1c0 0x420 0x4e4 0x00 0x01 0xd6 0x1cc 0x42c 0x00 0x00 0x00 0xd6 0x1d0 0x430 0x4e0 0x00 0x02 0xd6 0x1b8 0x418 0x00 0x05 0x00 0xd6 0x1bc 0x41c 0x00 0x05 0x00 0xd6>;
					phandle = <0x57>;
				};

				pciegrp {
					fsl,pins = <0x34 0x294 0x00 0x00 0x00 0x41>;
					phandle = <0x7c>;
				};

				usdhc3grp-100mhz {
					fsl,pins = <0x124 0x384 0x604 0x02 0x01 0x194 0x128 0x388 0x60c 0x02 0x01 0x1d4 0x108 0x368 0x610 0x02 0x01 0x1d4 0x10c 0x36c 0x614 0x02 0x01 0x1d4 0x110 0x370 0x618 0x02 0x01 0x1d4 0x114 0x374 0x61c 0x02 0x01 0x1d4 0x11c 0x37c 0x620 0x02 0x01 0x1d4 0xec 0x34c 0x624 0x02 0x01 0x1d4 0xf0 0x350 0x628 0x02 0x01 0x1d4 0xf4 0x354 0x62c 0x02 0x01 0x1d4 0xe8 0x348 0x630 0x02 0x01 0x194>;
					phandle = <0x4c>;
				};

				ft5x16_int_iogrp {
					fsl,pins = <0x44 0x2a4 0x00 0x00 0x00 0x16>;
					phandle = <0x3f>;
				};

				csi0_pwn_grp {
					fsl,pins = <0x130 0x390 0x00 0x05 0x00 0x19>;
					phandle = <0x30>;
				};

				usdhc1grp-200mhz {
					fsl,pins = <0x8c 0x2ec 0x00 0x00 0x00 0x196 0x90 0x2f0 0x00 0x00 0x00 0x1d6 0x94 0x2f4 0x00 0x00 0x00 0x1d6 0x98 0x2f8 0x00 0x00 0x00 0x1d6 0x9c 0x2fc 0x00 0x00 0x00 0x1d6 0xa0 0x300 0x00 0x00 0x00 0x1d6>;
					phandle = <0x43>;
				};

				csi_mclk_grp {
					fsl,pins = <0x50 0x2b0 0x00 0x06 0x00 0x59>;
				};

				i2c4grp {
					fsl,pins = <0x218 0x478 0x5bc 0x00 0x05 0x400001c3 0x21c 0x47c 0x5c0 0x00 0x05 0x400001c3>;
					phandle = <0x3e>;
				};

				i2c1grp {
					fsl,pins = <0x200 0x460 0x5a4 0x00 0x02 0x400001c3 0x204 0x464 0x5a8 0x00 0x02 0x400001c3>;
					phandle = <0x2c>;
				};

				usdhc1grp {
					fsl,pins = <0x8c 0x2ec 0x00 0x00 0x00 0x190 0x90 0x2f0 0x00 0x00 0x00 0x1d0 0x94 0x2f4 0x00 0x00 0x00 0x1d0 0x98 0x2f8 0x00 0x00 0x00 0x1d0 0x9c 0x2fc 0x00 0x00 0x00 0x1d0 0xa0 0x300 0x00 0x00 0x00 0x1d0>;
					phandle = <0x40>;
				};

				usdhc1grp-100mhz {
					fsl,pins = <0x8c 0x2ec 0x00 0x00 0x00 0x194 0x90 0x2f0 0x00 0x00 0x00 0x1d4 0x94 0x2f4 0x00 0x00 0x00 0x1d4 0x98 0x2f8 0x00 0x00 0x00 0x1d4 0x9c 0x2fc 0x00 0x00 0x00 0x1d4 0xa0 0x300 0x00 0x00 0x00 0x1d4>;
					phandle = <0x42>;
				};

				flexspi0grp {
					fsl,pins = <0xe0 0x340 0x00 0x01 0x00 0x1c2 0xe4 0x344 0x00 0x01 0x00 0x82 0xf8 0x358 0x00 0x01 0x00 0x82 0xfc 0x35c 0x00 0x01 0x00 0x82 0x100 0x360 0x00 0x01 0x00 0x82 0x104 0x364 0x00 0x01 0x00 0x82>;
					phandle = <0x4e>;
				};

				pwm2grp {
					fsl,pins = <0x40 0x2a0 0x00 0x02 0x00 0x116>;
					phandle = <0x21>;
				};

				uart2grp {
					fsl,pins = <0x228 0x488 0x5f0 0x00 0x06 0x49 0x22c 0x48c 0x00 0x00 0x00 0x49>;
					phandle = <0x28>;
				};

				sai5grp {
					fsl,pins = <0x138 0x398 0x510 0x03 0x00 0xd6 0x140 0x3a0 0x00 0x03 0x00 0xd6 0x144 0x3a4 0x4f0 0x00 0x00 0xd6 0x134 0x394 0x4f8 0x00 0x00 0xd6>;
					phandle = <0x58>;
				};

				lvds_panel_en {
					fsl,pins = <0x48 0x2a8 0x00 0x00 0x00 0x16>;
					phandle = <0xae>;
				};

				hoggrp {
					fsl,pins = <0x240 0x4a0 0x00 0x00 0x00 0x400001c3 0x244 0x4a4 0x00 0x00 0x00 0x400001c3 0x24c 0x4ac 0x00 0x00 0x00 0x40000019 0x248 0x4a8 0x00 0x00 0x00 0x40000019>;
					phandle = <0x18>;
				};

				fecgrp {
					fsl,pins = <0x158 0x3b8 0x00 0x04 0x00 0x03 0x15c 0x3bc 0x57c 0x04 0x01 0x03 0x160 0x3c0 0x580 0x04 0x01 0x91 0x164 0x3c4 0x584 0x04 0x01 0x91 0x168 0x3c8 0x00 0x04 0x00 0x91 0x16c 0x3cc 0x00 0x04 0x00 0x91 0x174 0x3d4 0x00 0x04 0x00 0x91 0x170 0x3d0 0x588 0x04 0x01 0x91 0x178 0x3d8 0x00 0x04 0x00 0x1f 0x17c 0x3dc 0x00 0x04 0x00 0x1f 0x180 0x3e0 0x00 0x04 0x00 0x1f 0x184 0x3e4 0x00 0x04 0x00 0x1f 0x188 0x3e8 0x00 0x04 0x00 0x1f 0x18c 0x3ec 0x00 0x04 0x00 0x1f 0x1d8 0x438 0x00 0x05 0x00 0x19>;
					phandle = <0x50>;
				};

				usdhc2grp-gpio {
					fsl,pins = <0xbc 0x31c 0x00 0x05 0x00 0x1c4 0xd8 0x338 0x00 0x05 0x00 0x41>;
					phandle = <0x46>;
				};

				usdhc2grp-200mhz {
					fsl,pins = <0xc0 0x320 0x00 0x00 0x00 0x196 0xc4 0x324 0x00 0x00 0x00 0x1d6 0xc8 0x328 0x00 0x00 0x00 0x1d6 0xcc 0x32c 0x00 0x00 0x00 0x1d6 0xd0 0x330 0x00 0x00 0x00 0x1d6 0xd4 0x334 0x00 0x00 0x00 0x1d6 0x24 0x284 0x00 0x01 0x00 0xc1>;
					phandle = <0x48>;
				};

				typec1muxgrp {
					fsl,pins = <0x198 0x3f8 0x00 0x05 0x00 0x16>;
					phandle = <0xa0>;
				};

				eqosgrp {
					fsl,pins = <0x54 0x2b4 0x00 0x00 0x00 0x03 0x58 0x2b8 0x590 0x00 0x01 0x03 0x7c 0x2dc 0x00 0x00 0x00 0x91 0x80 0x2e0 0x00 0x00 0x00 0x91 0x84 0x2e4 0x00 0x00 0x00 0x91 0x88 0x2e8 0x00 0x00 0x00 0x91 0x78 0x2d8 0x00 0x00 0x00 0x91 0x74 0x2d4 0x00 0x00 0x00 0x91 0x68 0x2c8 0x00 0x00 0x00 0x1f 0x64 0x2c4 0x00 0x00 0x00 0x1f 0x60 0x2c0 0x00 0x00 0x00 0x1f 0x5c 0x2bc 0x00 0x00 0x00 0x1f 0x6c 0x2cc 0x00 0x00 0x00 0x1f 0x70 0x2d0 0x00 0x00 0x00 0x1f 0x1dc 0x43c 0x00 0x05 0x00 0x19>;
					phandle = <0x53>;
				};

				i2c3grp {
					fsl,pins = <0x210 0x470 0x5b4 0x00 0x04 0x400001c3 0x214 0x474 0x5b8 0x00 0x04 0x400001c3>;
					phandle = <0x35>;
				};

				usdhc3grp {
					fsl,pins = <0x124 0x384 0x604 0x02 0x01 0x190 0x128 0x388 0x60c 0x02 0x01 0x1d0 0x108 0x368 0x610 0x02 0x01 0x1d0 0x10c 0x36c 0x614 0x02 0x01 0x1d0 0x110 0x370 0x618 0x02 0x01 0x1d0 0x114 0x374 0x61c 0x02 0x01 0x1d0 0x11c 0x37c 0x620 0x02 0x01 0x1d0 0xec 0x34c 0x624 0x02 0x01 0x1d0 0xf0 0x350 0x628 0x02 0x01 0x1d0 0xf4 0x354 0x62c 0x02 0x01 0x1d0 0xe8 0x348 0x630 0x02 0x01 0x190>;
					phandle = <0x4b>;
				};

				ecspi2grp {
					fsl,pins = <0x1f0 0x450 0x568 0x00 0x01 0x82 0x1f4 0x454 0x570 0x00 0x01 0x82 0x1f8 0x458 0x56c 0x00 0x01 0x82>;
					phandle = <0x23>;
				};

				pwm1grp {
					fsl,pins = <0x18 0x278 0x00 0x01 0x00 0x116>;
					phandle = <0x20>;
				};
			};

			caam_secvio {
				watchdog-tamper = "enabled";
				external-pin-tamper = "disabled";
				internal-boot-tamper = "enabled";
				interrupts = <0x00 0x14 0x04>;
				compatible = "fsl,imx6q-caam-secvio";
				jtag-tamper = "disabled";
			};

			gpio@30220000 {
				gpio-controller;
				interrupts = <0x00 0x44 0x04 0x00 0x45 0x04>;
				clocks = <0x03 0xc3>;
				compatible = "fsl,imx8mp-gpio\0fsl,imx35-gpio";
				#interrupt-cells = <0x02>;
				reg = <0x30220000 0x10000>;
				phandle = <0x32>;
				#gpio-cells = <0x02>;
				interrupt-controller;
			};

			tmu@30260000 {
				clocks = <0x03 0x119>;
				#thermal-sensor-cells = <0x01>;
				compatible = "fsl,imx8mp-tmu";
				reg = <0x30260000 0x10000>;
				phandle = <0x15>;
			};
		};

		caam-sm@100000 {
			compatible = "fsl,imx6q-caam-sm";
			reg = <0x100000 0x8000>;
		};

		bus@32c00000 {
			#address-cells = <0x01>;
			#size-cells = <0x01>;
			compatible = "simple-bus";
			ranges;
			reg = <0x32c00000 0x400000>;

			gasket@32ec0090 {
				compatible = "fsl,imx8mp-iomuxc-gpr\0syscon";
				reg = <0x32ec0090 0x28>;
				phandle = <0x74>;
			};

			gasket@32ec0060 {
				compatible = "fsl,imx8mp-iomuxc-gpr\0syscon";
				reg = <0x32ec0060 0x28>;
				phandle = <0x72>;
			};

			lcd-controller@32e90000 {
				power-domains = <0x0f>;
				#address-cells = <0x01>;
				clock-names = "pix\0disp-axi\0disp-apb";
				assigned-clocks = <0x03 0x121 0x03 0x61 0x03 0x62>;
				assigned-clock-parents = <0x03 0x28 0x03 0x41 0x03 0x38>;
				assigned-clock-rates = <0x00 0x1dcd6500 0xbebc200>;
				interrupts = <0x00 0x06 0x04>;
				clocks = <0x03 0x112 0x03 0x10e 0x03 0x10d>;
				#size-cells = <0x00>;
				compatible = "fsl,imx8mp-lcdif2";
				status = "okay";
				reg = <0x32e90000 0x10000>;

				port@0 {
					#address-cells = <0x01>;
					#size-cells = <0x00>;
					reg = <0x00>;
					phandle = <0x8a>;

					endpoint@1 {
						remote-endpoint = <0x62>;
						reg = <0x01>;
						phandle = <0x67>;
					};

					endpoint@0 {
						remote-endpoint = <0x61>;
						reg = <0x00>;
						phandle = <0x64>;
					};
				};
			};

			phy@32ec0128 {
				power-domains = <0x0f>;
				#address-cells = <0x01>;
				clock-names = "apb";
				clocks = <0x03 0x10d>;
				#size-cells = <0x00>;
				compatible = "fsl,imx8mp-lvds-phy";
				status = "okay";
				gpr = <0x5b>;

				port@0 {
					#phy-cells = <0x00>;
					reg = <0x00>;
					phandle = <0x63>;
				};

				port@1 {
					#phy-cells = <0x00>;
					reg = <0x01>;
					phandle = <0x66>;
				};
			};

			hdmiphy@32fdff00 {
				clock-output-names = "hdmi_phy";
				clock-names = "apb\0ref";
				resets = <0x69 0x01>;
				clocks = <0x68 0x1c 0x68 0x03>;
				#clock-cells = <0x01>;
				#phy-cells = <0x00>;
				compatible = "fsl,samsung-hdmi-phy";
				status = "disabled";
				reg = <0x32fdff00 0x100>;
				phandle = <0x6a>;
			};

			isi_chain@32e02000 {
				compatible = "fsl,imx8mp-iomuxc-gpr\0syscon";
				reg = <0x32e02000 0x04>;
				phandle = <0x70>;
			};

			camera {
				#address-cells = <0x01>;
				#size-cells = <0x01>;
				compatible = "fsl,mxc-md\0simple-bus";
				ranges;
				status = "okay";

				isp@32e20000 {
					power-domains = <0x71>;
					clock-names = "isp_root";
					assigned-clocks = <0x03 0x4a>;
					assigned-clock-parents = <0x03 0x40>;
					assigned-clock-rates = <0x1dcd6500>;
					id = <0x01>;
					interrupts = <0x00 0x4b 0x04>;
					clocks = <0x03 0x4a>;
					compatible = "fsl,imx8mp-isp";
					status = "disabled";
					reg = <0x32e20000 0x10000>;
				};

				isi@32e00000 {
					power-domains = <0x0f>;
					clock-names = "disp_axi\0disp_apb\0disp_axi_root\0disp_apb_root";
					assigned-clocks = <0x03 0x10e 0x03 0x10d>;
					assigned-clock-rates = <0x1dcd6500 0xbebc200>;
					interrupts = <0x00 0x10 0x04>;
					clocks = <0x03 0x61 0x03 0x62 0x03 0x10e 0x03 0x10d>;
					no-reset-control;
					compatible = "fsl,imx8mp-isi\0fsl,imx8mn-isi";
					status = "disabled";
					isi_chain = <0x70>;
					reg = <0x32e00000 0x2000>;
					interface = <0x02 0x00 0x02>;

					m2m_device {
						compatible = "imx-isi-m2m";
						status = "disabled";
					};

					cap_device {
						compatible = "imx-isi-capture";
						status = "disabled";
					};
				};

				isi@32e02000 {
					power-domains = <0x0f>;
					clock-names = "disp_axi\0disp_apb\0disp_axi_root\0disp_apb_root";
					assigned-clocks = <0x03 0x10e 0x03 0x10d>;
					assigned-clock-rates = <0x1dcd6500 0xbebc200>;
					interrupts = <0x00 0x2a 0x04>;
					clocks = <0x03 0x61 0x03 0x62 0x03 0x10e 0x03 0x10d>;
					no-reset-control;
					compatible = "fsl,imx8mp-isi\0fsl,imx8mn-isi";
					status = "okay";
					reg = <0x32e02000 0x2000>;
					interface = <0x03 0x00 0x02>;

					m2m_device {
						status = "okay";
					};

					cap_device {
						compatible = "imx-isi-capture";
						status = "okay";
					};
				};

				dwe@32e30000 {
					id = <0x00>;
					interrupts = <0x00 0x64 0x04>;
					compatible = "fsl,imx8mp-dwe";
					status = "okay";
					reg = <0x32e30000 0x10000>;
				};

				csi@32e40000 {
					power-domains = <0x5a>;
					#address-cells = <0x01>;
					clock-names = "mipi_clk\0disp_axi\0disp_apb";
					assigned-clocks = <0x03 0xaa>;
					assigned-clock-parents = <0x03 0x41>;
					bus-width = <0x04>;
					assigned-clock-rates = <0x1dcd6500>;
					interrupts = <0x00 0x11 0x04>;
					clocks = <0x03 0xaa 0x03 0x61 0x03 0x62>;
					#size-cells = <0x00>;
					no-reset-control;
					clock-frequency = <0x1dcd6500>;
					csi-gpr = <0x72>;
					compatible = "fsl,imx8mp-mipi-csi\0fsl,imx8mn-mipi-csi";
					status = "okay";
					reg = <0x32e40000 0x10000>;
					gpr = <0x5b>;

					port@0 {
						reg = <0x00>;

						endpoint {
							data-lanes = <0x04>;
							csis-hs-settle = <0x10>;
							remote-endpoint = <0x73>;
							phandle = <0x34>;
						};
					};
				};

				isp@32e10000 {
					power-domains = <0x71>;
					clock-names = "isp_root";
					assigned-clocks = <0x03 0x4a>;
					assigned-clock-parents = <0x03 0x40>;
					assigned-clock-rates = <0x1dcd6500>;
					id = <0x00>;
					interrupts = <0x00 0x4a 0x04>;
					clocks = <0x03 0x4a>;
					compatible = "fsl,imx8mp-isp";
					status = "okay";
					reg = <0x32e10000 0x10000>;
				};

				dwe_dup@32e30000 {
					id = <0x01>;
					interrupts = <0x00 0x64 0x04>;
					compatible = "fsl,imx8mp-dwe";
					status = "disabled";
					reg = <0x32e30000 0x10000>;
				};

				csi@32e50000 {
					power-domains = <0x75>;
					#address-cells = <0x01>;
					clock-names = "mipi_clk\0disp_axi\0disp_apb";
					assigned-clocks = <0x03 0xad>;
					assigned-clock-parents = <0x03 0x41>;
					bus-width = <0x04>;
					assigned-clock-rates = <0xfdad680>;
					interrupts = <0x00 0x50 0x04>;
					clocks = <0x03 0xad 0x03 0x61 0x03 0x62>;
					#size-cells = <0x00>;
					no-reset-control;
					clock-frequency = <0xfdad680>;
					csi-gpr = <0x74>;
					compatible = "fsl,imx8mp-mipi-csi\0fsl,imx8mn-mipi-csi";
					status = "okay";
					reg = <0x32e50000 0x10000>;
					gpr = <0x5b>;

					port@1 {
						reg = <0x01>;

						endpoint {
							data-lanes = <0x02>;
							csis-wclk;
							csis-hs-settle = <0x0d>;
							csis-clk-settle = <0x02>;
							remote-endpoint = <0x76>;
							phandle = <0x33>;
						};
					};
				};
			};

			blk-ctl@32ec0000 {
				clocks = <0x03 0x10d>;
				compatible = "fsl,imx8mp-mediamix-blk-ctl\0syscon";
				reg = <0x32ec0000 0x10000>;
				phandle = <0x5b>;
			};

			ldb@32ec005c {
				power-domains = <0x0f>;
				#address-cells = <0x01>;
				clock-names = "ldb";
				assigned-clocks = <0x03 0xae>;
				assigned-clock-parents = <0x03 0x28>;
				clocks = <0x03 0x122>;
				#size-cells = <0x00>;
				compatible = "fsl,imx8mp-ldb";
				status = "okay";
				gpr = <0x5b>;

				lvds-channel@0 {
					#address-cells = <0x01>;
					phy-names = "ldb_phy";
					#size-cells = <0x00>;
					fsl,data-mapping = "spwg";
					fsl,data-width = <0x18>;
					status = "okay";
					phys = <0x63>;
					reg = <0x00>;

					port@0 {
						reg = <0x00>;

						endpoint {
							remote-endpoint = <0x64>;
							phandle = <0x61>;
						};
					};

					port@1 {
						reg = <0x01>;

						endpoint {
							remote-endpoint = <0x65>;
							phandle = <0xaf>;
						};
					};
				};

				lvds-channel@1 {
					#address-cells = <0x01>;
					phy-names = "ldb_phy";
					#size-cells = <0x00>;
					status = "disabled";
					phys = <0x66>;
					reg = <0x01>;

					port@0 {
						reg = <0x00>;

						endpoint {
							remote-endpoint = <0x67>;
							phandle = <0x62>;
						};
					};
				};
			};

			hdmi@32fd8000 {
				power-domains = <0x6e>;
				phy-names = "hdmi";
				clock-names = "iahb\0isfr\0phy_int\0prep_clk\0skp_clk\0sfr_clk\0pix_clk\0cec_clk\0apb_clk\0hpi_clk\0fdcc_ref\0pipe_clk";
				assigned-clocks = <0x03 0x63 0x03 0x64 0x03 0xa7>;
				assigned-clock-parents = <0x03 0x38 0x03 0x40 0x03 0x02>;
				assigned-clock-rates = <0xbebc200 0x1dcd6500 0x16e3600>;
				resets = <0x69 0x00>;
				interrupts = <0x00 0x04>;
				clocks = <0x03 0x63 0x03 0xa7 0x68 0x1d 0x68 0x1b 0x68 0x1a 0x68 0x19 0x68 0x18 0x68 0x15 0x68 0x14 0x68 0x13 0x68 0x0e 0x68 0x24>;
				interrupt-parent = <0x6b>;
				compatible = "fsl,imx8mp-hdmi";
				status = "disabled";
				phys = <0x6a>;
				reg = <0x32fd8000 0x7eff>;
				gpr = <0x6d>;

				port@0 {

					endpoint {
						remote-endpoint = <0x6f>;
						phandle = <0x6c>;
					};
				};
			};

			irqsteer@32fc2000 {
				clock-names = "ipg";
				assigned-clocks = <0x03 0x63>;
				assigned-clock-parents = <0x03 0x38>;
				assigned-clock-rates = <0xbebc200>;
				resets = <0x69 0x05>;
				interrupts = <0x00 0x2b 0x04>;
				clocks = <0x68 0x06>;
				interrupt-parent = <0x01>;
				compatible = "fsl,imx-irqsteer";
				#interrupt-cells = <0x01>;
				status = "disabled";
				reg = <0x32fc2000 0x1000>;
				phandle = <0x6b>;
				fsl,num-irqs = <0x40>;
				fsl,channel = <0x01>;
				interrupt-controller;
			};

			hdmi-pai-pvi@32fc4000 {
				clock-names = "pvi_clk\0pai_clk";
				resets = <0x69 0x02 0x69 0x03>;
				clocks = <0x68 0x20 0x68 0x17>;
				compatible = "fsl,imx8mp-hdmi-pavi";
				status = "disabled";
				reg = <0x32fc4000 0x1000>;
				reset-names = "pai_rst\0pvi_rst";
			};

			hdmimix@32fc0000 {
				compatible = "fsl,imx8mp-audiomix\0fsl,imx8mp-hdmimix";
				reg = <0x32fc0000 0x1000>;

				clock-controller {
					clock-names = "dummy";
					clocks = <0x03 0x00>;
					#clock-cells = <0x01>;
					compatible = "fsl,imx8mp-hdmimix-clk";
					status = "disabled";
					phandle = <0x68>;
				};

				reset-controller {
					#reset-cells = <0x01>;
					compatible = "fsl,imx8mp-hdmimix-reset";
					status = "disabled";
					phandle = <0x69>;
				};
			};

			mipi_dsi@32e60000 {
				power-domains = <0x5a>;
				timing = <0x203>;
				#address-cells = <0x01>;
				clock-names = "cfg\0pll-ref";
				assigned-clocks = <0x03 0xab>;
				assigned-clock-parents = <0x03 0x02>;
				assigned-clock-rates = <0x16e3600>;
				interrupts = <0x00 0x12 0x04>;
				timing2 = <0x30305>;
				clocks = <0x03 0x10d 0x03 0xab>;
				#size-cells = <0x00>;
				compatible = "fsl,imx8mp-mipi-dsim";
				status = "okay";
				pmsreg = <0x8644>;
				reg = <0x32e60000 0x10000>;
				blk-ctl = <0x5b>;
				timing1 = <0x20d0803>;

				port@0 {

					endpoint {
						remote-endpoint = <0x5c>;
						phandle = <0x60>;
					};
				};

				port@1 {

					endpoint {
						remote-endpoint = <0x5f>;
						phandle = <0xb0>;
					};
				};

				mipi_panel {
					panel-height-mm = <0x79>;
					pinctrl-names = "default";
					video-mode = <0x02>;
					pinctrl-0 = <0x5d>;
					backlight = <0x5e>;
					panel-width-mm = <0x44>;
					enable-gpio = <0x2e 0x07 0x00>;
					compatible = "forlinx,mipi-dsi";
					status = "okay";
					dsi-lanes = <0x04>;
					reg = <0x00>;

					display-timings {

						timings {
							vfront-porch = <0x0c>;
							vback-porch = <0x17>;
							de-active = <0x00>;
							hsync-len = <0x46>;
							vactive = <0x258>;
							clock-frequency = <0x2aea540>;
							hsync-active = <0x00>;
							hactive = <0x400>;
							vsync-active = <0x00>;
							vsync-len = <0x0a>;
							pixelclk-active = <0x00>;
							hback-porch = <0xa0>;
							hfront-porch = <0xa0>;
						};
					};
				};
			};

			hdmi-blk@32fc0000 {
				compatible = "syscon";
				reg = <0x32fc0000 0x1000>;
				phandle = <0x6d>;
			};

			media_gpr@32ec0008 {
				compatible = "fsl,imx8mp-iomuxc-gpr\0syscon";
				reg = <0x32ec0008 0x04>;
			};

			lcd-controller@32fc6000 {
				power-domains = <0x10>;
				#address-cells = <0x01>;
				clock-names = "pix\0disp-axi\0disp-apb\0mix_apb\0mix_axi\0xtl_24m\0mix_pix\0lcdif_apb\0lcdif_axi\0lcdif_pdi\0lcdif_pix\0lcdif_spu\0noc_hdmi";
				assigned-clocks = <0x03 0x64 0x03 0x63>;
				assigned-clock-parents = <0x03 0x40 0x03 0x38>;
				assigned-clock-rates = <0x1dcd6500 0xbebc200>;
				resets = <0x69 0x07>;
				interrupts = <0x08 0x04>;
				clocks = <0x6a 0x00 0x03 0x64 0x03 0x63 0x68 0x00 0x68 0x01 0x68 0x03 0x68 0x05 0x68 0x09 0x68 0x0a 0x68 0x0b 0x68 0x0c 0x68 0x0d 0x68 0x07>;
				thres-low = <0x01 0x02>;
				#size-cells = <0x00>;
				interrupt-parent = <0x6b>;
				compatible = "fsl,imx8mp-lcdif3";
				thres-high = <0x03 0x04>;
				status = "disabled";
				reg = <0x32fc6000 0x10000>;

				port@0 {
					reg = <0x00>;
					phandle = <0x8b>;

					endpoint {
						remote-endpoint = <0x6c>;
						phandle = <0x6f>;
					};
				};
			};

			lcd-controller@32e80000 {
				power-domains = <0x0f>;
				#address-cells = <0x01>;
				clock-names = "pix\0disp-axi\0disp-apb";
				assigned-clocks = <0x03 0xac 0x03 0x61 0x03 0x62>;
				assigned-clock-parents = <0x03 0x28 0x03 0x41 0x03 0x38>;
				assigned-clock-rates = <0x00 0x1dcd6500 0xbebc200>;
				interrupts = <0x00 0x05 0x04>;
				clocks = <0x03 0x111 0x03 0x10e 0x03 0x10d>;
				#size-cells = <0x00>;
				compatible = "fsl,imx8mp-lcdif1";
				status = "disabled";
				reg = <0x32e80000 0x10000>;
				blk-ctl = <0x5b>;

				port@0 {
					reg = <0x00>;
					phandle = <0x89>;

					endpoint {
						remote-endpoint = <0x60>;
						phandle = <0x5c>;
					};
				};
			};
		};

		bus@30400000 {
			#address-cells = <0x01>;
			#size-cells = <0x01>;
			compatible = "simple-bus";
			ranges;
			reg = <0x30400000 0x400000>;

			pwm@30670000 {
				pinctrl-names = "default";
				pinctrl-0 = <0x21>;
				clock-names = "ipg\0per";
				interrupts = <0x00 0x52 0x04>;
				clocks = <0x03 0xdd 0x03 0xdd>;
				#pwm-cells = <0x02>;
				compatible = "fsl,imx8mp-pwm\0fsl,imx27-pwm";
				status = "okay";
				reg = <0x30670000 0x10000>;
				phandle = <0xab>;
			};

			pwm@30680000 {
				clock-names = "ipg\0per";
				interrupts = <0x00 0x53 0x04>;
				clocks = <0x03 0xde 0x03 0xde>;
				#pwm-cells = <0x02>;
				compatible = "fsl,imx8mp-pwm\0fsl,imx27-pwm";
				status = "disabled";
				reg = <0x30680000 0x10000>;
			};

			pwm@30690000 {
				clock-names = "ipg\0per";
				interrupts = <0x00 0x54 0x04>;
				clocks = <0x03 0xdf 0x03 0xdf>;
				#pwm-cells = <0x02>;
				compatible = "fsl,imx8mp-pwm\0fsl,imx27-pwm";
				status = "disabled";
				reg = <0x30690000 0x10000>;
			};

			pwm@30660000 {
				pinctrl-names = "default";
				pinctrl-0 = <0x20>;
				clock-names = "ipg\0per";
				assigned-clocks = <0x03 0x97>;
				assigned-clock-parents = <0x03 0x02>;
				assigned-clock-rates = <0x16e3600>;
				interrupts = <0x00 0x51 0x04>;
				clocks = <0x03 0xdc 0x03 0xdc>;
				#pwm-cells = <0x02>;
				compatible = "fsl,imx8mp-pwm\0fsl,imx27-pwm";
				status = "okay";
				reg = <0x30660000 0x10000>;
				phandle = <0xac>;
			};

			timer@306a0000 {
				clock-names = "per";
				interrupts = <0x00 0x2f 0x04>;
				clocks = <0x1b>;
				compatible = "nxp,sysctr-timer";
				reg = <0x306a0000 0x20000>;
			};
		};

		bus@30c00000 {
			#address-cells = <0x01>;
			#size-cells = <0x01>;
			compatible = "simple-bus";
			ranges;
			reg = <0x30c00000 0x400000>;

			spba-bus@30c00000 {
				#address-cells = <0x01>;
				#size-cells = <0x01>;
				compatible = "fsl,spba-bus\0simple-bus";
				ranges;
				reg = <0x30c00000 0x100000>;

				sai@30c20000 {
					power-domains = <0x56>;
					clock-names = "bus\0mclk0\0mclk1\0mclk2\0mclk3";
					fsl,dataline = <0x00 0x0f 0x0f>;
					interrupts = <0x00 0x60 0x04>;
					clocks = <0x3b 0x04 0x03 0x00 0x3b 0x05 0x03 0x00 0x03 0x00>;
					dma-names = "rx\0tx";
					compatible = "fsl,imx8mq-sai\0fsl,imx6sx-sai";
					fsl,shared-interrupt;
					status = "disabled";
					reg = <0x30c20000 0x10000>;
					dmas = <0x55 0x02 0x02 0x00 0x55 0x03 0x02 0x00>;
				};

				sai@30c60000 {
					power-domains = <0x56>;
					clock-names = "bus\0mclk0\0mclk1\0mclk2\0mclk3";
					interrupts = <0x00 0x5a 0x04>;
					clocks = <0x3b 0x10 0x03 0x00 0x3b 0x11 0x03 0x00 0x03 0x00>;
					dma-names = "rx\0tx";
					compatible = "fsl,imx8mq-sai\0fsl,imx6sx-sai";
					fsl,shared-interrupt;
					status = "disabled";
					reg = <0x30c60000 0x10000>;
					dmas = <0x55 0x0a 0x02 0x00 0x55 0x0b 0x02 0x00>;
				};

				micfil@30ca0000 {
					power-domains = <0x56>;
					clock-names = "ipg_clk\0ipg_clk_app\0pll8k\0pll11k\0clkext3";
					interrupts = <0x00 0x6d 0x04 0x00 0x6e 0x04 0x00 0x2c 0x04 0x00 0x2d 0x04>;
					clocks = <0x3b 0x19 0x3b 0x27 0x03 0x26 0x03 0x27 0x03 0x06>;
					dma-names = "rx";
					compatible = "fsl,imx8mp-micfil";
					status = "disabled";
					reg = <0x30ca0000 0x10000>;
					dmas = <0x55 0x18 0x19 0x80000000>;
				};

				xcvr@30cc0000 {
					power-domains = <0x56>;
					clock-names = "ipg\0phy\0spba\0pll_ipg";
					reg-names = "ram\0regs\0rxfifo\0txfifo";
					resets = <0x59 0x00>;
					interrupts = <0x00 0x80 0x04 0x00 0x81 0x04 0x00 0x92 0x04>;
					clocks = <0x3b 0x1f 0x3b 0x26 0x3b 0x1c 0x3b 0x23>;
					dma-names = "rx\0tx";
					#sound-dai-cells = <0x00>;
					compatible = "fsl,imx8mp-xcvr";
					status = "okay";
					reg = <0x30cc0000 0x800 0x30cc0800 0x400 0x30cc0c00 0x80 0x30cc0e00 0x80>;
					phandle = <0xaa>;
					dmas = <0x55 0x1e 0x02 0x00 0x55 0x1f 0x02 0x00>;
				};

				sai@30c30000 {
					power-domains = <0x56>;
					pinctrl-names = "default";
					pinctrl-0 = <0x57>;
					clock-names = "bus\0mclk0\0mclk1\0mclk2\0mclk3";
					assigned-clocks = <0x03 0x7d>;
					assigned-clock-parents = <0x03 0x26>;
					fsl,dataline = <0x00 0x03 0x03>;
					assigned-clock-rates = <0xbb8000>;
					interrupts = <0x00 0x32 0x04>;
					clocks = <0x3b 0x08 0x03 0x00 0x3b 0x09 0x03 0x00 0x03 0x00>;
					dma-names = "rx\0tx";
					compatible = "fsl,imx8mq-sai\0fsl,imx6sx-sai";
					fsl,shared-interrupt;
					status = "okay";
					fsl,sai-mclk-direction-output;
					reg = <0x30c30000 0x10000>;
					phandle = <0xa6>;
					dmas = <0x55 0x04 0x02 0x00 0x55 0x05 0x02 0x00>;
				};

				sai@30c80000 {
					power-domains = <0x56>;
					clock-names = "bus\0mclk0\0mclk1\0mclk2\0mclk3";
					interrupts = <0x00 0x6f 0x04>;
					clocks = <0x3b 0x14 0x03 0x00 0x3b 0x15 0x03 0x00 0x03 0x00>;
					dma-names = "rx\0tx";
					compatible = "fsl,imx8mq-sai\0fsl,imx6sx-sai";
					fsl,shared-interrupt;
					status = "disabled";
					reg = <0x30c80000 0x10000>;
					dmas = <0x55 0x0c 0x02 0x00 0x55 0x0d 0x02 0x00>;
				};

				easrc@30c90000 {
					power-domains = <0x56>;
					fsl,asrc-width = <0x10>;
					clock-names = "mem";
					interrupts = <0x00 0x7a 0x04>;
					fsl,asrc-rate = <0xbb80>;
					clocks = <0x3b 0x18>;
					dma-names = "ctx0_rx\0ctx0_tx\0ctx1_rx\0ctx1_tx\0ctx2_rx\0ctx2_tx\0ctx3_rx\0ctx3_tx";
					fsl,easrc-ram-script-name = "imx/easrc/easrc-imx8mn.bin";
					compatible = "fsl,imx8mn-easrc";
					status = "okay";
					reg = <0x30c90000 0x10000>;
					phandle = <0xa8>;
					dmas = <0x55 0x10 0x17 0x00 0x55 0x11 0x17 0x00 0x55 0x12 0x17 0x00 0x55 0x13 0x17 0x00 0x55 0x14 0x17 0x00 0x55 0x15 0x17 0x00 0x55 0x16 0x17 0x00 0x55 0x17 0x17 0x00>;
				};

				sai@30c10000 {
					power-domains = <0x56>;
					clock-names = "bus\0mclk0\0mclk1\0mclk2\0mclk3";
					fsl,dataline = <0x00 0xff 0xff>;
					interrupts = <0x00 0x5f 0x04>;
					clocks = <0x3b 0x00 0x03 0x00 0x3b 0x01 0x03 0x00 0x03 0x00>;
					dma-names = "rx\0tx";
					compatible = "fsl,imx8mq-sai\0fsl,imx6sx-sai";
					fsl,shared-interrupt;
					status = "disabled";
					reg = <0x30c10000 0x10000>;
					dmas = <0x55 0x00 0x02 0x00 0x55 0x01 0x02 0x00>;
				};

				sai@30c50000 {
					power-domains = <0x56>;
					pinctrl-names = "default";
					pinctrl-0 = <0x58>;
					clock-names = "bus\0mclk0\0mclk1\0mclk2\0mclk3";
					assigned-clocks = <0x03 0x7f>;
					assigned-clock-parents = <0x03 0x26>;
					fsl,dataline = <0x00 0x0f 0x0f>;
					assigned-clock-rates = <0xbb8000>;
					interrupts = <0x00 0x5a 0x04>;
					clocks = <0x3b 0x0c 0x03 0x00 0x3b 0x0d 0x03 0x00 0x03 0x00>;
					dma-names = "rx\0tx";
					#sound-dai-cells = <0x00>;
					compatible = "fsl,imx8mq-sai\0fsl,imx6sx-sai";
					fsl,shared-interrupt;
					status = "okay";
					reg = <0x30c50000 0x10000>;
					phandle = <0xa3>;
					dmas = <0x55 0x08 0x02 0x00 0x55 0x09 0x02 0x00>;
				};

				aud2htx@30cb0000 {
					power-domains = <0x56>;
					clock-names = "bus";
					interrupts = <0x00 0x82 0x04>;
					clocks = <0x3b 0x21>;
					dma-names = "tx";
					compatible = "fsl,imx8mp-aud2htx";
					status = "okay";
					reg = <0x30cb0000 0x10000>;
					phandle = <0xa5>;
					dmas = <0x55 0x1a 0x02 0x00>;
				};
			};

			dma-controller@30e00000 {
				power-domains = <0x56>;
				clock-names = "ipg\0ahb";
				interrupts = <0x00 0x22 0x04>;
				clocks = <0x3b 0x1b 0x3b 0x1b>;
				fsl,sdma-ram-script-name = "imx/sdma/sdma-imx7d.bin";
				compatible = "fsl,imx8mp-sdma\0fsl,imx7d-sdma";
				status = "disabled";
				reg = <0x30e00000 0x10000>;
				#dma-cells = <0x03>;
				fsl,ratio-1-1;
			};

			audiomix@30e20000 {
				compatible = "fsl,imx8mp-audiomix";
				reg = <0x30e20000 0x10000>;

				audiomix_dsp {
					compatible = "fsl,audiomix-dsp";
				};

				clock-controller {
					power-domains = <0x56>;
					clock-names = "audio_root";
					clocks = <0x03 0x11c>;
					#clock-cells = <0x01>;
					compatible = "fsl,imx8mp-audiomix-clk";
					phandle = <0x3b>;
				};

				reset-controller {
					power-domains = <0x56>;
					#reset-cells = <0x01>;
					compatible = "fsl,imx8mp-audiomix-reset";
					phandle = <0x59>;
				};
			};

			dma-controller@30e10000 {
				power-domains = <0x56>;
				clock-names = "ipg\0ahb";
				interrupts = <0x00 0x67 0x04>;
				clocks = <0x03 0x6f 0x03 0x6c>;
				fsl,sdma-ram-script-name = "imx/sdma/sdma-imx7d.bin";
				compatible = "fsl,imx8mp-sdma\0fsl,imx7d-sdma";
				status = "okay";
				reg = <0x30e10000 0x10000>;
				phandle = <0x55>;
				#dma-cells = <0x03>;
				fsl,ratio-1-1;
			};

			mu2@30e60000 {
				fsl,dsp_ap_mu_id = <0x02>;
				interrupts = <0x00 0x88 0x04>;
				clocks = <0x3b 0x24>;
				#mbox-cells = <0x02>;
				compatible = "fsl,imx8-mu-dsp\0fsl,imx6sx-mu";
				status = "okay";
				reg = <0x30e60000 0x10000>;
				phandle = <0x88>;
			};
		};
	};

	i2c-rpbus-3 {
		compatible = "fsl,i2c-rpbus";
		status = "disabled";
	};

	clock-osc-24m {
		clock-output-names = "osc_24m";
		#clock-cells = <0x00>;
		clock-frequency = <0x16e3600>;
		compatible = "fixed-clock";
		phandle = <0x1b>;
	};

	etm@28740000 {
		arm,primecell-periphid = <0xbb95d>;
		clock-names = "apb_pclk";
		clocks = <0x03 0x5d>;
		cpu = <0x14>;
		compatible = "arm,coresight-etm4x\0arm,primecell";
		status = "disabled";
		reg = <0x00 0x28740000 0x00 0x10000>;

		out-ports {

			port {

				endpoint {
					remote-endpoint = <0x92>;
					phandle = <0x96>;
				};
			};
		};
	};

	rpmsg {
		vdev-nums = <0x01>;
		memory-region = <0x0b>;
		compatible = "fsl,imx8mq-rpmsg";
		status = "okay";
		reg = <0x00 0x55000000 0x00 0x10000>;
		mboxes = <0x08 0x00 0x01 0x08 0x01 0x01 0x08 0x03 0x01>;
		mbox-names = "tx\0rx\0rxdb";
	};

	lvds0_panel {
		pinctrl-0 = <0xae>;
		width-mm = <0xda>;
		backlight = <0xad>;
		enable-gpio = <0x2e 0x0d 0x00>;
		panel-type = "lvds";
		bmp-logo = "logo-1280x800.bmp";
		compatible = "forlinx,panel\0panel-lvds";
		data-mapping = "vesa-24";
		height-mm = <0x8a>;

		port {

			endpoint {
				remote-endpoint = <0xaf>;
				phandle = <0x65>;
			};
		};

		panel-timing {
			vfront-porch = <0x02>;
			vback-porch = <0x01>;
			hsync-len = <0x0a>;
			vactive = <0x320>;
			clock-frequency = <0x44aa200>;
			hactive = <0x500>;
			vsync-len = <0x14>;
			hback-porch = <0x0a>;
			hfront-porch = <0x8c>;
		};
	};

	vpu_vc8000e@38320000 {
		power-domains = <0x85>;
		clock-names = "clk_hantro_vc8000e\0clk_hantro_vc8000e_bus";
		reg-names = "regs_hantro_vc8000e";
		assigned-clocks = <0x03 0xb5 0x03 0x60>;
		assigned-clock-parents = <0x03 0x41 0x03 0x38>;
		assigned-clock-rates = <0x1dcd6500 0x2faf0800>;
		interrupts = <0x00 0x1e 0x04>;
		clocks = <0x03 0x109 0x03 0x11a>;
		compatible = "nxp,imx8mp-hantro-vc8000e";
		status = "okay";
		interrupt-names = "irq_hantro_vc8000e";
		reg = <0x00 0x38320000 0x00 0x10000>;
	};

	sound-wm8960 {
		codec-master;
		mic-det-gpios = <0x38 0x1c 0x00>;
		model = "wm8960-audio";
		hp-det = <0x03 0x00>;
		hp-det-gpios = <0x38 0x1c 0x00>;
		audio-routing = "Headphone Jack\0HP_L\0Headphone Jack\0HP_R\0Ext Spk\0SPK_LP\0Ext Spk\0SPK_LN\0Ext Spk\0SPK_RP\0Ext Spk\0SPK_RN\0LINPUT1\0Mic Jack\0RINPUT1\0Mic Jack\0Mic Jack\0MICB\0CPU-Playback\0ASRC-Playback\0Playback\0CPU-Playback\0ASRC-Capture\0CPU-Capture\0CPU-Capture\0Capture";
		compatible = "fsl,imx7d-evk-wm8960\0fsl,imx-audio-wm8960";
		cpu-dai = <0xa6>;
		status = "okay";
		enable-gpios = <0x38 0x1d 0x00>;
		asrc-controller = <0xa8>;
		audio-codec = <0xa7>;
	};

	dsi-host {
		compatible = "samsung,sec-mipi-dsi";
		status = "okay";
	};

	memory@40000000 {
		device_type = "memory";
		reg = <0x00 0x40000000 0x00 0x16000000 0x00 0x58000000 0x00 0xa8000000 0x01 0x00 0x00 0x40000000>;
	};

	gpmi-nand@33002000 {
		#address-cells = <0x01>;
		clock-names = "gpmi_io\0gpmi_bch_apb";
		reg-names = "gpmi-nand\0bch";
		interrupts = <0x00 0x0e 0x04>;
		clocks = <0x03 0xe3 0x03 0xe4>;
		#size-cells = <0x01>;
		dma-names = "rx-tx";
		compatible = "fsl,imx7d-gpmi-nand";
		status = "disabled";
		interrupt-names = "bch";
		reg = <0x00 0x33002000 0x00 0x2000 0x00 0x33004000 0x00 0x4000>;
		dmas = <0x77 0x00>;
	};

	gpu2d@38008000 {
		power-domains = <0x7e>;
		clock-names = "core\0axi\0ahb";
		assigned-clocks = <0x03 0x47 0x03 0x65 0x03 0x66>;
		assigned-clock-parents = <0x03 0x41 0x03 0x38 0x03 0x38>;
		assigned-clock-rates = <0x3b9aca00 0x2faf0800 0x17d78400>;
		interrupts = <0x00 0x19 0x04>;
		clocks = <0x03 0xf7 0x03 0x65 0x03 0x66>;
		compatible = "fsl,imx8-gpu";
		status = "okay";
		reg = <0x00 0x38008000 0x00 0x8000>;
		phandle = <0x8e>;
	};

	etm@28640000 {
		arm,primecell-periphid = <0xbb95d>;
		clock-names = "apb_pclk";
		clocks = <0x03 0x5d>;
		cpu = <0x13>;
		compatible = "arm,coresight-etm4x\0arm,primecell";
		status = "disabled";
		reg = <0x00 0x28640000 0x00 0x10000>;

		out-ports {

			port {

				endpoint {
					remote-endpoint = <0x91>;
					phandle = <0x95>;
				};
			};
		};
	};

	sound-xcvr {
		model = "imx-audio-xcvr";
		compatible = "fsl,imx-audio-xcvr";
		cpu-dai = <0xaa>;
	};

	bt_sco_codec {
		#sound-dai-cells = <0x01>;
		compatible = "linux,bt-sco";
		phandle = <0xa4>;
	};

	display-subsystem {
		ports = <0x89 0x8a 0x8b>;
		compatible = "fsl,imx-display-subsystem";
	};

	interrupt-controller@38800000 {
		interrupts = <0x01 0x09 0x04>;
		interrupt-parent = <0x01>;
		compatible = "arm,gic-v3";
		#interrupt-cells = <0x03>;
		reg = <0x00 0x38800000 0x00 0x10000 0x00 0x38880000 0x00 0xc0000>;
		phandle = <0x01>;
		interrupt-controller;
	};

	thermal-zones {

		cpu-thermal {
			polling-delay = <0x7d0>;
			polling-delay-passive = <0xfa>;
			thermal-sensors = <0x15 0x00>;

			trips {

				trip0 {
					temperature = <0x17318>;
					hysteresis = <0x7d0>;
					type = "passive";
					phandle = <0x16>;
				};

				trip1 {
					temperature = <0x19a28>;
					hysteresis = <0x7d0>;
					type = "critical";
				};
			};

			cooling-maps {

				map0 {
					trip = <0x16>;
					cooling-device = <0x11 0xffffffff 0xffffffff 0x12 0xffffffff 0xffffffff 0x13 0xffffffff 0xffffffff 0x14 0xffffffff 0xffffffff>;
				};
			};
		};

		soc-thermal {
			polling-delay = <0x7d0>;
			polling-delay-passive = <0xfa>;
			thermal-sensors = <0x15 0x01>;

			trips {

				trip0 {
					temperature = <0x17318>;
					hysteresis = <0x7d0>;
					type = "passive";
				};

				trip1 {
					temperature = <0x19a28>;
					hysteresis = <0x7d0>;
					type = "critical";
				};
			};
		};
	};

	clock-ext3 {
		clock-output-names = "clk_ext3";
		#clock-cells = <0x00>;
		clock-frequency = <0x7ed6b40>;
		compatible = "fixed-clock";
		phandle = <0x1e>;
	};

	gpu3d@38000000 {
		power-domains = <0x7d>;
		clock-names = "core\0shader\0axi\0ahb";
		assigned-clocks = <0x03 0x45 0x03 0x46 0x03 0x65 0x03 0x66>;
		assigned-clock-parents = <0x03 0x41 0x03 0x41 0x03 0x38 0x03 0x38>;
		assigned-clock-rates = <0x3b9aca00 0x3b9aca00 0x2faf0800 0x17d78400>;
		interrupts = <0x00 0x03 0x04>;
		clocks = <0x03 0xf8 0x03 0x58 0x03 0x65 0x03 0x66>;
		compatible = "fsl,imx8-gpu";
		status = "okay";
		reg = <0x00 0x38000000 0x00 0x8000>;
		phandle = <0x8c>;
	};

	pcie@33800000 {
		power-domains = <0x78>;
		pinctrl-names = "default";
		#address-cells = <0x03>;
		phy-names = "pcie-phy";
		pinctrl-0 = <0x7c>;
		clock-names = "pcie\0pcie_aux\0pcie_phy\0pcie_bus";
		reg-names = "dbi\0config";
		assigned-clocks = <0x03 0x49 0x03 0x78>;
		assigned-clock-parents = <0x03 0x40 0x03 0x39>;
		resets = <0x79 0x1a 0x79 0x1b 0x79 0x1c 0x79 0x32 0x79 0x1d>;
		interrupts = <0x00 0x8c 0x04 0x00 0x7f 0x04>;
		clocks = <0x03 0x5b 0x03 0x78 0x03 0x77 0x03 0xd9>;
		fsl,max-link-speed = <0x03>;
		interrupt-map = <0x00 0x00 0x00 0x01 0x01 0x00 0x7e 0x04 0x00 0x00 0x00 0x02 0x01 0x00 0x7d 0x04 0x00 0x00 0x00 0x03 0x01 0x00 0x7c 0x04 0x00 0x00 0x00 0x04 0x01 0x00 0x7b 0x04>;
		#size-cells = <0x02>;
		reset-gpio = <0x2e 0x08 0x00>;
		device_type = "pci";
		interrupt-map-mask = <0x00 0x00 0x00 0x07>;
		num-lanes = <0x01>;
		compatible = "fsl,imx8mp-pcie\0snps,dw-pcie";
		ranges = <0x81000000 0x00 0x00 0x00 0x1ff80000 0x00 0x10000 0x82000000 0x00 0x18000000 0x00 0x18000000 0x00 0x7f00000>;
		#interrupt-cells = <0x01>;
		status = "okay";
		interrupt-names = "msi\0dma";
		phys = <0x7a>;
		fsl,imx8mp-hsio-mix = <0x7b>;
		ext_osc = <0x01>;
		reg = <0x00 0x33800000 0x00 0x400000 0x00 0x1ff00000 0x00 0x80000>;
		reset-names = "pciephy\0pciephy_perst\0apps\0clkreq\0turnoff";
	};

	leds {
		pinctrl-names = "default";
		pinctrl-0 = <0x9d>;
		compatible = "gpio-leds";

		led2 {
			linux,default-trigger = "timer";
			default-state = "on";
			led-pattern = <0x64 0x1f4>;
			gpios = <0x25 0x09 0x01>;
		};

		heartbeat {
			linux,default-trigger = "heartbeat";
			default-state = "off";
			gpios = <0x32 0x10 0x00>;
		};

		led1 {
			linux,default-trigger = "disk-activity";
			default-state = "on";
			gpios = <0x25 0x08 0x01>;
		};
	};

	hsio-mix@32f10000 {
		compatible = "fsl,imx8mp-hsio-mix";
		reg = <0x00 0x32f10000 0x00 0x08>;
		phandle = <0x7b>;
	};

	psci {
		method = "smc";
		compatible = "arm,psci-1.0";
	};

	etm@28540000 {
		arm,primecell-periphid = <0xbb95d>;
		clock-names = "apb_pclk";
		clocks = <0x03 0x5d>;
		cpu = <0x12>;
		compatible = "arm,coresight-etm4x\0arm,primecell";
		status = "disabled";
		reg = <0x00 0x28540000 0x00 0x10000>;

		out-ports {

			port {

				endpoint {
					remote-endpoint = <0x90>;
					phandle = <0x94>;
				};
			};
		};
	};

	vpu_g1@38300000 {
		power-domains = <0x83>;
		clock-names = "clk_hantro\0clk_hantro_bus";
		reg-names = "regs_hantro";
		assigned-clocks = <0x03 0x72 0x03 0x60>;
		assigned-clock-parents = <0x03 0x38 0x03 0x38>;
		assigned-clock-rates = <0x2faf0800 0x2faf0800>;
		interrupts = <0x00 0x07 0x04>;
		clocks = <0x03 0x106 0x03 0x11a>;
		compatible = "nxp,imx8mm-hantro\0nxp,imx8mp-hantro";
		status = "okay";
		interrupt-names = "irq_hantro";
		reg = <0x00 0x38300000 0x00 0x100000>;
	};

	clock-ext1 {
		clock-output-names = "clk_ext1";
		#clock-cells = <0x00>;
		clock-frequency = <0x7ed6b40>;
		compatible = "fixed-clock";
		phandle = <0x1c>;
	};

	usb-phy@382f0040 {
		clock-names = "phy";
		assigned-clocks = <0x03 0x93>;
		assigned-clock-parents = <0x03 0x02>;
		clocks = <0x03 0x100>;
		#phy-cells = <0x00>;
		compatible = "fsl,imx8mp-usb-phy";
		status = "okay";
		reg = <0x00 0x382f0040 0x00 0x40>;
		phandle = <0x82>;
		fsl,phy-tx-preemp-amp-tune = <0x02>;
	};

	usb@32f10108 {
		power-domains = <0x0c>;
		#address-cells = <0x02>;
		clock-names = "hsio\0suspend";
		interrupts = <0x00 0x95 0x04>;
		clocks = <0x03 0x10c 0x03 0xff>;
		#size-cells = <0x02>;
		compatible = "fsl,imx8mp-dwc3";
		ranges;
		status = "okay";
		reg = <0x00 0x32f10108 0x00 0x08>;

		dwc3@38200000 {
			phy-names = "usb2-phy\0usb3-phy";
			clock-names = "bus_early\0ref\0suspend";
			assigned-clocks = <0x03 0x49>;
			assigned-clock-parents = <0x03 0x40>;
			snps,dis-u2-freeclk-exists-quirk;
			assigned-clock-rates = <0x1dcd6500>;
			interrupts = <0x00 0x29 0x04>;
			clocks = <0x03 0x5b 0x03 0x92 0x03 0xff>;
			compatible = "snps,dwc3";
			status = "okay";
			phys = <0x82 0x82>;
			reg = <0x00 0x38200000 0x00 0x10000>;
			dr_mode = "host";
		};
	};

	sound-bt-sco {
		simple-audio-card,bitclock-master = <0xa2>;
		simple-audio-card,name = "bt-sco-audio";
		simple-audio-card,format = "dsp_a";
		simple-audio-card,bitclock-inversion;
		compatible = "simple-audio-card";
		simple-audio-card,frame-master = <0xa2>;

		simple-audio-card,cpu {
			dai-tdm-slot-num = <0x02>;
			phandle = <0xa2>;
			sound-dai = <0xa3>;
			dai-tdm-slot-width = <0x10>;
		};

		simple-audio-card,codec {
			sound-dai = <0xa4 0x01>;
		};
	};

	opp-table {
		opp-shared;
		compatible = "operating-points-v2";
		phandle = <0x04>;

		opp-1200000000 {
			opp-microvolt = <0xcf850>;
			opp-hz = <0x00 0x47868c00>;
			opp-supported-hw = <0x8a0 0x07>;
			opp-suspend;
			clock-latency-ns = <0x249f0>;
		};

		opp-1600000000 {
			opp-microvolt = <0xe7ef0>;
			opp-hz = <0x00 0x5f5e1000>;
			opp-supported-hw = <0xa0 0x07>;
			opp-suspend;
			clock-latency-ns = <0x249f0>;
		};

		opp-1800000000 {
			opp-microvolt = <0xf4240>;
			opp-hz = <0x00 0x6b49d200>;
			opp-supported-hw = <0x20 0x03>;
			opp-suspend;
			clock-latency-ns = <0x249f0>;
		};
	};

	regulator-audio-pwr {
		regulator-max-microvolt = <0x325aa0>;
		gpio = <0x38 0x1d 0x00>;
		regulator-always-on;
		enable-active-high;
		regulator-min-microvolt = <0x325aa0>;
		regulator-name = "audio-pwr";
		compatible = "regulator-fixed";
		phandle = <0x3c>;
	};

	vipsi@38500000 {
		power-domains = <0x86>;
		clock-names = "core\0shader\0axi\0ahb";
		assigned-clocks = <0x03 0x44 0x03 0x69 0x03 0x6a>;
		assigned-clock-parents = <0x03 0x41 0x03 0x38 0x03 0x38>;
		assigned-clock-rates = <0x3b9aca00 0x2faf0800 0x17d78400>;
		interrupts = <0x00 0x0d 0x04>;
		clocks = <0x03 0x10b 0x03 0x10b 0x03 0x69 0x03 0x6a>;
		compatible = "fsl,imx8-gpu\0fsl,imx8-vipsi";
		status = "okay";
		reg = <0x00 0x38500000 0x00 0x20000>;
		phandle = <0x8d>;
	};

	lvds_backlight {
		default-brightness-level = <0xfa>;
		compatible = "pwm-backlight";
		status = "okay";
		brightness-levels = <0x00 0x01 0x02 0x03 0x04 0x05 0x06 0x07 0x08 0x09 0x0a 0x0b 0x0c 0x0d 0x0e 0x0f 0x10 0x11 0x12 0x13 0x14 0x15 0x16 0x17 0x18 0x19 0x1a 0x1b 0x1c 0x1d 0x1e 0x1f 0x20 0x21 0x22 0x23 0x24 0x25 0x26 0x27 0x28 0x29 0x2a 0x2b 0x2c 0x2d 0x2e 0x2f 0x30 0x31 0x32 0x33 0x34 0x35 0x36 0x37 0x38 0x39 0x3a 0x3b 0x3c 0x3d 0x3e 0x3f 0x40 0x41 0x42 0x43 0x44 0x45 0x46 0x47 0x48 0x49 0x4a 0x4b 0x4c 0x4d 0x4e 0x4f 0x50 0x51 0x52 0x53 0x54 0x55 0x56 0x57 0x58 0x59 0x5a 0x5b 0x5c 0x5d 0x5e 0x5f 0x60 0x61 0x62 0x63 0x64 0x65 0x66 0x67 0x68 0x69 0x6a 0x6b 0x6c 0x6d 0x6e 0x6f 0x70 0x71 0x72 0x73 0x74 0x75 0x76 0x77 0x78 0x79 0x7a 0x7b 0x7c 0x7d 0x7e 0x7f 0x80 0x81 0x82 0x83 0x84 0x85 0x86 0x87 0x88 0x89 0x8a 0x8b 0x8c 0x8d 0x8e 0x8f 0x90 0x91 0x92 0x93 0x94 0x95 0x96 0x97 0x98 0x99 0x9a 0x9b 0x9c 0x9d 0x9e 0x9f 0xa0 0xa1 0xa2 0xa3 0xa4 0xa5 0xa6 0xa7 0xa8 0xa9 0xaa 0xab 0xac 0xad 0xae 0xaf 0xb0 0xb1 0xb2 0xb3 0xb4 0xb5 0xb6 0xb7 0xb8 0xb9 0xba 0xbb 0xbc 0xbd 0xbe 0xbf 0xc0 0xc1 0xc2 0xc3 0xc4 0xc5 0xc6 0xc7 0xc8 0xc9 0xca 0xcb 0xcc 0xcd 0xce 0xcf 0xd0 0xd1 0xd2 0xd3 0xd4 0xd5 0xd6 0xd7 0xd8 0xd9 0xda 0xdb 0xdc 0xdd 0xde 0xdf 0xe0 0xe1 0xe2 0xe3 0xe4 0xe5 0xe6 0xe7 0xe8 0xe9 0xea 0xeb 0xec 0xed 0xee 0xef 0xf0 0xf1 0xf2 0xf3 0xf4 0xf5 0xf6 0xf7 0xf8 0xf9 0xfa 0xfb 0xfc 0xfd 0xfe 0xff>;
		phandle = <0xad>;
		is-forlinx;
		pwms = <0xab 0x00 0xc350>;
	};

	memory-controller@3d400000 {
		interrupts = <0x00 0x93 0x04>;
		compatible = "fsl,imx8mp-ddrc";
		reg = <0x00 0x3d400000 0x00 0x400000>;
	};

	dsp@3b6e8000 {
		power-domains = <0x56>;
		fsl,dsp-firmware = "imx/dsp/hifi4.bin";
		clock-names = "ocram\0core\0debug\0mu2";
		memory-region = <0x87>;
		clocks = <0x3b 0x20 0x3b 0x1d 0x3b 0x1e 0x3b 0x24>;
		compatible = "fsl,imx8mp-dsp-v1";
		status = "okay";
		reg = <0x00 0x3b6e8000 0x00 0x88000>;
		mboxes = <0x88 0x02 0x00 0x88 0x02 0x01 0x88 0x03 0x00 0x88 0x03 0x01>;
		mbox-names = "txdb0\0txdb1\0rxdb0\0rxdb1";
	};

	regulator-usb1-vbus {
		regulator-max-microvolt = <0x4c4b40>;
		pinctrl-names = "default";
		gpio = <0x2e 0x0e 0x00>;
		pinctrl-0 = <0x9f>;
		enable-active-high;
		regulator-min-microvolt = <0x4c4b40>;
		regulator-name = "usb1_host_vbus";
		compatible = "regulator-fixed";
		phandle = <0x37>;
	};

	etm@28440000 {
		arm,primecell-periphid = <0xbb95d>;
		clock-names = "apb_pclk";
		clocks = <0x03 0x5d>;
		cpu = <0x11>;
		compatible = "arm,coresight-etm4x\0arm,primecell";
		status = "disabled";
		reg = <0x00 0x28440000 0x00 0x10000>;

		out-ports {

			port {

				endpoint {
					remote-endpoint = <0x8f>;
					phandle = <0x93>;
				};
			};
		};
	};

	keys {
		pinctrl-names = "default";
		pinctrl-0 = <0x9e>;
		compatible = "gpio-keys";

		up {
			label = "GPIO Key UP";
			linux,code = <0x67>;
			debounce-interval = <0x14>;
			gpios = <0x38 0x18 0x01>;
		};

		down {
			label = "GPIO Key DOWN";
			linux,code = <0x6c>;
			debounce-interval = <0x14>;
			gpios = <0x38 0x12 0x01>;
		};
	};

	usb-phy@381f0040 {
		fsl,pcs-tx-deemph-3p5db = <0x21>;
		clock-names = "phy";
		assigned-clocks = <0x03 0x93>;
		assigned-clock-parents = <0x03 0x02>;
		vbus-power-supply = <0x7f>;
		fsl,phy-pcs-tx-swing-full = <0x7f>;
		clocks = <0x03 0x100>;
		fsl,phy-tx-rise-tune = <0x00>;
		#phy-cells = <0x00>;
		compatible = "fsl,imx8mp-usb-phy";
		fsl,phy-tx-vref-tune = <0x06>;
		status = "okay";
		reg = <0x00 0x381f0040 0x00 0x40>;
		phandle = <0x80>;
		fsl,phy-comp-dis-tune = <0x07>;
		fsl,phy-tx-preemp-amp-tune = <0x03>;
	};

	timer {
		arm,no-tick-in-suspend;
		interrupts = <0x01 0x0d 0x3f08 0x01 0x0e 0x3f08 0x01 0x0b 0x3f08 0x01 0x0a 0x3f08>;
		interrupt-parent = <0x01>;
		clock-frequency = <0x7a1200>;
		compatible = "arm,armv8-timer";
	};

	etr@28c06000 {
		clock-names = "apb_pclk";
		clocks = <0x03 0x5d>;
		compatible = "arm,coresight-tmc\0arm,primecell";
		status = "disabled";
		reg = <0x00 0x28c06000 0x00 0x1000>;

		in-ports {

			port {

				endpoint {
					remote-endpoint = <0x9c>;
					phandle = <0x9b>;
				};
			};
		};
	};

	forlinx_control {
		status = "disabled";
		video-hdmi = "on";
		video-mipi = "off";
		video-lvds = "on";
	};

	aliases {
		ethernet0 = "/soc@0/bus@30800000/ethernet@30be0000";
		gpio0 = "/soc@0/bus@30000000/gpio@30200000";
		isp0 = "/soc@0/bus@32c00000/camera/isp@32e10000";
		mmc1 = "/soc@0/bus@30800000/mmc@30b50000";
		serial3 = "/soc@0/bus@30800000/serial@30a60000";
		isi1 = "/soc@0/bus@32c00000/camera/isi@32e02000";
		serial1 = "/soc@0/bus@30800000/serial@30890000";
		csi1 = "/soc@0/bus@32c00000/camera/csi@32e50000";
		gpio3 = "/soc@0/bus@30000000/gpio@30230000";
		ethernet1 = "/soc@0/bus@30800000/ethernet@30bf0000";
		gpio1 = "/soc@0/bus@30000000/gpio@30210000";
		isp1 = "/soc@0/bus@32c00000/camera/isp@32e20000";
		mmc2 = "/soc@0/bus@30800000/mmc@30b60000";
		mmc0 = "/soc@0/bus@30800000/mmc@30b40000";
		serial2 = "/soc@0/bus@30800000/serial@30880000";
		gpio4 = "/soc@0/bus@30000000/gpio@30240000";
		isi0 = "/soc@0/bus@32c00000/camera/isi@32e00000";
		serial0 = "/soc@0/bus@30800000/serial@30860000";
		csi0 = "/soc@0/bus@32c00000/camera/csi@32e40000";
		gpio2 = "/soc@0/bus@30000000/gpio@30220000";
	};

	firmware {

		optee {
			method = "smc";
			compatible = "linaro,optee-tz";
		};
	};

	dsi_backlight {
		default-brightness-level = <0xfa>;
		compatible = "pwm-backlight";
		status = "okay";
		brightness-levels = <0x00 0x01 0x02 0x03 0x04 0x05 0x06 0x07 0x08 0x09 0x0a 0x0b 0x0c 0x0d 0x0e 0x0f 0x10 0x11 0x12 0x13 0x14 0x15 0x16 0x17 0x18 0x19 0x1a 0x1b 0x1c 0x1d 0x1e 0x1f 0x20 0x21 0x22 0x23 0x24 0x25 0x26 0x27 0x28 0x29 0x2a 0x2b 0x2c 0x2d 0x2e 0x2f 0x30 0x31 0x32 0x33 0x34 0x35 0x36 0x37 0x38 0x39 0x3a 0x3b 0x3c 0x3d 0x3e 0x3f 0x40 0x41 0x42 0x43 0x44 0x45 0x46 0x47 0x48 0x49 0x4a 0x4b 0x4c 0x4d 0x4e 0x4f 0x50 0x51 0x52 0x53 0x54 0x55 0x56 0x57 0x58 0x59 0x5a 0x5b 0x5c 0x5d 0x5e 0x5f 0x60 0x61 0x62 0x63 0x64 0x65 0x66 0x67 0x68 0x69 0x6a 0x6b 0x6c 0x6d 0x6e 0x6f 0x70 0x71 0x72 0x73 0x74 0x75 0x76 0x77 0x78 0x79 0x7a 0x7b 0x7c 0x7d 0x7e 0x7f 0x80 0x81 0x82 0x83 0x84 0x85 0x86 0x87 0x88 0x89 0x8a 0x8b 0x8c 0x8d 0x8e 0x8f 0x90 0x91 0x92 0x93 0x94 0x95 0x96 0x97 0x98 0x99 0x9a 0x9b 0x9c 0x9d 0x9e 0x9f 0xa0 0xa1 0xa2 0xa3 0xa4 0xa5 0xa6 0xa7 0xa8 0xa9 0xaa 0xab 0xac 0xad 0xae 0xaf 0xb0 0xb1 0xb2 0xb3 0xb4 0xb5 0xb6 0xb7 0xb8 0xb9 0xba 0xbb 0xbc 0xbd 0xbe 0xbf 0xc0 0xc1 0xc2 0xc3 0xc4 0xc5 0xc6 0xc7 0xc8 0xc9 0xca 0xcb 0xcc 0xcd 0xce 0xcf 0xd0 0xd1 0xd2 0xd3 0xd4 0xd5 0xd6 0xd7 0xd8 0xd9 0xda 0xdb 0xdc 0xdd 0xde 0xdf 0xe0 0xe1 0xe2 0xe3 0xe4 0xe5 0xe6 0xe7 0xe8 0xe9 0xea 0xeb 0xec 0xed 0xee 0xef 0xf0 0xf1 0xf2 0xf3 0xf4 0xf5 0xf6 0xf7 0xf8 0xf9 0xfa 0xfb 0xfc 0xfd 0xfe 0xff>;
		phandle = <0x5e>;
		is-forlinx;
		pwms = <0xac 0x00 0xc350>;
	};

	chosen {
		bootargs = "console=ttymxc1,115200 root=/dev/mmcblk2p2 rootwait rw";
		stdout-path = "/soc@0/bus@30800000/serial@30890000";
	};

	funnel@28c03000 {
		clock-names = "apb_pclk";
		clocks = <0x03 0x5d>;
		compatible = "arm,coresight-dynamic-funnel\0arm,primecell";
		status = "disabled";
		reg = <0x00 0x28c03000 0x00 0x1000>;

		in-ports {
			#address-cells = <0x01>;
			#size-cells = <0x00>;

			port@0 {
				reg = <0x00>;

				endpoint {
					remote-endpoint = <0x98>;
					phandle = <0x97>;
				};
			};

			port@1 {
				reg = <0x01>;

				endpoint {
				};
			};

			port@2 {
				reg = <0x02>;

				endpoint {
				};
			};
		};

		out-ports {

			port {

				endpoint {
					remote-endpoint = <0x99>;
					phandle = <0x9a>;
				};
			};
		};
	};

	mix_gpu_ml {
		reg-names = "phys_baseaddr\0contiguous_mem";
		compatible = "fsl,imx8mp-gpu\0fsl,imx8-gpu-ss";
		status = "okay";
		reg = <0x00 0x40000000 0x00 0xc0000000 0x00 0x00 0x00 0x10000000>;
		cores = <0x8c 0x8d 0x8e>;
	};

	cbtl04gp {
		pinctrl-names = "default";
		orientation-switch;
		switch-gpios = <0x38 0x14 0x01>;
		pinctrl-0 = <0xa0>;
		compatible = "nxp,cbtl04gp";

		port {

			endpoint {
				remote-endpoint = <0xa1>;
				phandle = <0x3a>;
			};
		};
	};

	clock-ext4 {
		clock-output-names = "clk_ext4";
		#clock-cells = <0x00>;
		clock-frequency = <0x7ed6b40>;
		compatible = "fixed-clock";
		phandle = <0x1f>;
	};

	ddr_pmu@3d800000 {
		interrupts = <0x00 0x62 0x04>;
		compatible = "fsl,imx8mp-ddr-pmu\0fsl,imx8m-ddr-pmu";
		reg = <0x00 0x3d800000 0x00 0x400000>;
	};

	etf@28c04000 {
		clock-names = "apb_pclk";
		clocks = <0x03 0x5d>;
		compatible = "arm,coresight-tmc\0arm,primecell";
		status = "disabled";
		reg = <0x00 0x28c04000 0x00 0x1000>;

		in-ports {

			port {

				endpoint {
					remote-endpoint = <0x9a>;
					phandle = <0x99>;
				};
			};
		};

		out-ports {

			port {

				endpoint {
					remote-endpoint = <0x9b>;
					phandle = <0x9c>;
				};
			};
		};
	};

	sound-nau8822 {
		codec-master;
		mic-det-gpios = <0x38 0x1c 0x00>;
		model = "nau8822-audio";
		hp-det-gpios = <0x38 0x1c 0x00>;
		audio-routing = "Headphone Jack\0LHP\0Headphone Jack\0RHP\0Ext Spk\0LSPK\0Ext Spk\0RSPK\0LMICN\0Mic Jack\0LMICP\0Mic Jack\0RMICN\0Mic Jack\0RMICP\0Mic Jack\0CPU-Playback\0ASRC-Playback\0Playback\0CPU-Playback\0ASRC-Capture\0CPU-Capture\0CPU-Capture\0Capture";
		compatible = "fsl,imx7d-evk-nau8822\0fsl,imx-audio-nau8822";
		cpu-dai = <0xa6>;
		status = "disabled";
		asrc-controller = <0xa8>;
		audio-codec = <0xa9>;
	};

	mipi_panel_uboot {
		panel-height-mm = <0x79>;
		pinctrl-names = "default";
		video-mode = <0x02>;
		pinctrl-0 = <0x5d>;
		backlight = <0x5e>;
		panel-width-mm = <0x44>;
		enable-gpio = <0x2e 0x07 0x00>;
		panel-type = "mipi";
		bmp-logo = "logo-1024x600.bmp";
		compatible = "forlinx,panel";
		status = "okay";
		dsi-lanes = <0x04>;
		reg = <0x00>;

		port {

			endpoint {
				remote-endpoint = <0xb0>;
				phandle = <0x5f>;
			};
		};

		display-timings {

			timings {
				vfront-porch = <0x0c>;
				vback-porch = <0x17>;
				de-active = <0x00>;
				hsync-len = <0x46>;
				vactive = <0x258>;
				clock-frequency = <0x2aea540>;
				hsync-active = <0x00>;
				hactive = <0x400>;
				vsync-active = <0x00>;
				vsync-len = <0x0a>;
				pixelclk-active = <0x00>;
				hback-porch = <0xa0>;
				hfront-porch = <0xa0>;
			};
		};
	};

	usb@32f10100 {
		power-domains = <0x0c>;
		#address-cells = <0x02>;
		clock-names = "hsio\0suspend";
		interrupts = <0x00 0x94 0x04>;
		clocks = <0x03 0x10c 0x03 0xff>;
		#size-cells = <0x02>;
		compatible = "fsl,imx8mp-dwc3";
		ranges;
		status = "okay";
		reg = <0x00 0x32f10100 0x00 0x08>;

		dwc3@38100000 {
			srp-disable;
			hnp-disable;
			adp-disable;
			phy-names = "usb2-phy\0usb3-phy";
			clock-names = "bus_early\0ref\0suspend";
			assigned-clocks = <0x03 0x49>;
			assigned-clock-parents = <0x03 0x40>;
			snps,dis-u2-freeclk-exists-quirk;
			usb-role-switch;
			assigned-clock-rates = <0x1dcd6500>;
			interrupts = <0x00 0x28 0x04>;
			clocks = <0x03 0x5b 0x03 0x92 0x03 0xff>;
			compatible = "snps,dwc3";
			status = "okay";
			phys = <0x80 0x80>;
			reg = <0x00 0x38100000 0x00 0x10000>;
			dr_mode = "otg";

			port {

				endpoint {
					remote-endpoint = <0x81>;
					phandle = <0x39>;
				};
			};
		};
	};

	funnel {
		compatible = "arm,coresight-static-funnel";
		status = "disabled";

		in-ports {
			#address-cells = <0x01>;
			#size-cells = <0x00>;

			port@0 {
				reg = <0x00>;

				endpoint {
					remote-endpoint = <0x93>;
					phandle = <0x8f>;
				};
			};

			port@3 {
				reg = <0x03>;

				endpoint {
					remote-endpoint = <0x96>;
					phandle = <0x92>;
				};
			};

			port@1 {
				reg = <0x01>;

				endpoint {
					remote-endpoint = <0x94>;
					phandle = <0x90>;
				};
			};

			port@2 {
				reg = <0x02>;

				endpoint {
					remote-endpoint = <0x95>;
					phandle = <0x91>;
				};
			};
		};

		out-ports {

			port {

				endpoint {
					remote-endpoint = <0x97>;
					phandle = <0x98>;
				};
			};
		};
	};

	pcie-phy@32f00000 {
		clock-names = "phy";
		assigned-clocks = <0x03 0x77>;
		assigned-clock-parents = <0x03 0x02>;
		clocks = <0x03 0x77>;
		#phy-cells = <0x00>;
		compatible = "fsl,imx8mp-pcie-phy";
		status = "okay";
		ext_osc = <0x01>;
		reg = <0x00 0x32f00000 0x00 0x10000>;
		phandle = <0x7a>;
	};

	usdhc1_pwrseq {
		wifi_reg_on;
		reset-gpios = <0x49 0x08 0x01>;
		compatible = "mmc-pwrseq-simple";
		phandle = <0x44>;
	};

	pmu {
		interrupt-affinity = <0x11 0x12 0x13 0x14>;
		interrupts = <0x01 0x07 0x3f04>;
		interrupt-parent = <0x01>;
		compatible = "arm,armv8-pmuv3";
	};

	cpus {
		#address-cells = <0x01>;
		#size-cells = <0x00>;

		cpu@1 {
			clock-latency = <0xee6c>;
			clocks = <0x03 0x11f>;
			cpu-idle-states = <0x06>;
			device_type = "cpu";
			compatible = "arm,cortex-a53";
			next-level-cache = <0x02>;
			reg = <0x01>;
			enable-method = "psci";
			phandle = <0x12>;
			operating-points-v2 = <0x04>;
			#cooling-cells = <0x02>;
		};

		l2-cache0 {
			compatible = "cache";
			phandle = <0x02>;
		};

		idle-states {
			entry-method = "psci";

			cpu-pd-wait {
				entry-latency-us = <0x3e8>;
				local-timer-stop;
				exit-latency-us = <0x2bc>;
				wakeup-latency-us = <0x5dc>;
				arm,psci-suspend-param = <0x10033>;
				compatible = "arm,idle-state";
				phandle = <0x06>;
				min-residency-us = <0xa8c>;
			};
		};

		cpu@2 {
			clock-latency = <0xee6c>;
			clocks = <0x03 0x11f>;
			cpu-idle-states = <0x06>;
			device_type = "cpu";
			compatible = "arm,cortex-a53";
			next-level-cache = <0x02>;
			reg = <0x02>;
			enable-method = "psci";
			phandle = <0x13>;
			operating-points-v2 = <0x04>;
			#cooling-cells = <0x02>;
		};

		cpu@0 {
			nvmem-cells = <0x05>;
			clock-latency = <0xee6c>;
			cpu-supply = <0x07>;
			clocks = <0x03 0x11f>;
			cpu-idle-states = <0x06>;
			device_type = "cpu";
			compatible = "arm,cortex-a53";
			next-level-cache = <0x02>;
			nvmem-cell-names = "speed_grade";
			reg = <0x00>;
			enable-method = "psci";
			phandle = <0x11>;
			operating-points-v2 = <0x04>;
			#cooling-cells = <0x02>;
		};

		cpu@3 {
			clock-latency = <0xee6c>;
			clocks = <0x03 0x11f>;
			cpu-idle-states = <0x06>;
			device_type = "cpu";
			compatible = "arm,cortex-a53";
			next-level-cache = <0x02>;
			reg = <0x03>;
			enable-method = "psci";
			phandle = <0x14>;
			operating-points-v2 = <0x04>;
			#cooling-cells = <0x02>;
		};
	};

	clock-ext2 {
		clock-output-names = "clk_ext2";
		#clock-cells = <0x00>;
		clock-frequency = <0x7ed6b40>;
		compatible = "fixed-clock";
		phandle = <0x1d>;
	};

	imx_ion {
		compatible = "fsl,mxc-ion";
		fsl,heap-id = <0x00>;
	};

	reserved-memory {
		#address-cells = <0x02>;
		#size-cells = <0x02>;
		ranges;

		linux,cma {
			linux,cma-default;
			alloc-ranges = <0x00 0x40000000 0x00 0xc0000000>;
			compatible = "shared-dma-pool";
			size = <0x00 0x3c000000>;
			reusable;
		};

		video-logo@0x54000000 {
			reg = <0x00 0x54000000 0x00 0xff0000>;
			no-map;
		};

		optee_shm@0x57c00000 {
			reg = <0x00 0x57c00000 0x00 0x400000>;
			no-map;
		};

		rpmsg@0x55800000 {
			reg = <0x00 0x55800000 0x00 0x800000>;
			no-map;
		};

		rsc-table {
			reg = <0x00 0x550ff000 0x00 0x1000>;
			no-map;
		};

		optee_core@0x56000000 {
			reg = <0x00 0x56000000 0x00 0x1c00000>;
			no-map;
		};

		vdev0vring1@55008000 {
			compatible = "shared-dma-pool";
			reg = <0x00 0x55008000 0x00 0x8000>;
			phandle = <0x0a>;
			no-map;
		};

		vdevbuffer@55400000 {
			compatible = "shared-dma-pool";
			reg = <0x00 0x55400000 0x00 0x100000>;
			phandle = <0x0b>;
			no-map;
		};

		ocram@900000 {
			reg = <0x00 0x900000 0x00 0x70000>;
			no-map;
		};

		imx8mp-cm7 {
			memory-region = <0x09 0x0a 0x0b>;
			clocks = <0x03 0x55>;
			compatible = "fsl,imx8mp-cm7";
			status = "okay";
			mboxes = <0x08 0x00 0x01 0x08 0x01 0x01 0x08 0x03 0x01>;
			mbox-names = "tx\0rx\0rxdb";
			rsc-da = <0x55000000>;
		};

		vdev0vring0@55000000 {
			compatible = "shared-dma-pool";
			reg = <0x00 0x55000000 0x00 0x8000>;
			phandle = <0x09>;
			no-map;
		};

		dsp@92400000 {
			reg = <0x00 0x92400000 0x00 0x2000000>;
			phandle = <0x87>;
			no-map;
		};
	};

	vpu_g2@38310000 {
		power-domains = <0x84>;
		clock-names = "clk_hantro\0clk_hantro_bus";
		reg-names = "regs_hantro";
		assigned-clocks = <0x03 0x73 0x03 0x60 0x03 0x17>;
		assigned-clock-parents = <0x03 0x2b 0x03 0x38>;
		assigned-clock-rates = <0x29b92700 0x2faf0800 0x29b92700>;
		interrupts = <0x00 0x08 0x04>;
		clocks = <0x03 0x10a 0x03 0x11a>;
		compatible = "nxp,imx8mm-hantro\0nxp,imx8mp-hantro";
		status = "okay";
		interrupt-names = "irq_hantro";
		reg = <0x00 0x38310000 0x00 0x100000>;
	};

	clock-osc-32k {
		clock-output-names = "osc_32k";
		#clock-cells = <0x00>;
		clock-frequency = <0x8000>;
		compatible = "fixed-clock";
		phandle = <0x1a>;
	};

	regulator-usdhc2 {
		regulator-max-microvolt = <0x325aa0>;
		gpio = <0x49 0x13 0x00>;
		off-on-delay-us = <0x2ee0>;
		enable-active-high;
		regulator-min-microvolt = <0x325aa0>;
		regulator-name = "VSD_3V3";
		startup-delay-us = <0x64>;
		compatible = "regulator-fixed";
		phandle = <0x4a>;
	};

	dma-apbh@33000000 {
		interrupts = <0x00 0x0c 0x04 0x00 0x0c 0x04 0x00 0x0c 0x04 0x00 0x0c 0x04>;
		clocks = <0x03 0xe4>;
		compatible = "fsl,imx7d-dma-apbh\0fsl,imx28-dma-apbh";
		interrupt-names = "gpmi0\0gpmi1\0gpmi2\0gpmi3";
		reg = <0x00 0x33000000 0x00 0x2000>;
		phandle = <0x77>;
		dma-channels = <0x04>;
		#dma-cells = <0x01>;
	};

	pcie_ep@33800000 {
		power-domains = <0x78>;
		pinctrl-names = "default";
		phy-names = "pcie-phy";
		pinctrl-0 = <0x7c>;
		clock-names = "pcie\0pcie_aux\0pcie_phy\0pcie_bus";
		reg-names = "regs\0addr_space";
		assigned-clocks = <0x03 0x49 0x03 0x78>;
		assigned-clock-parents = <0x03 0x40 0x03 0x39>;
		num-ob-windows = <0x04>;
		resets = <0x79 0x1a 0x79 0x1b 0x79 0x1c 0x79 0x32 0x79 0x1d>;
		interrupts = <0x00 0x7f 0x04>;
		clocks = <0x03 0x5b 0x03 0x78 0x03 0x77 0x03 0xd9>;
		fsl,max-link-speed = <0x03>;
		num-lanes = <0x01>;
		compatible = "fsl,imx8mp-pcie-ep";
		status = "disabled";
		interrupt-names = "dma";
		phys = <0x7a>;
		fsl,imx8mp-hsio-mix = <0x7b>;
		ext_osc = <0x01>;
		reg = <0x00 0x33800000 0x00 0x400000 0x00 0x18000000 0x00 0x8000000>;
		reset-names = "pciephy\0pciephy_perst\0apps\0clkreq\0turnoff";
		num-ib-windows = <0x04>;
	};
};
